AUTOSAR XML (schema 4-0-3)
standard types defined: uint8, Boolean, UInt16, UInt8
package /AUTOSAR_Platform/DataConstrs
  range DC_Boolean: raw 0..1
  range DC_UInt16: raw 0..65535
  range DC_UInt8: raw 0..255
package /DataTypes/Units
  unit NoUnit1: display-name=NoUnit, factor-si-to-unit=1, offset-si-to-unit=0
package /PATAC/Facility/DataTypes/Implementation
  compu method COMPU_Boolean: 0=FALSE, 1=TRUE
  unit NoUnit: factor-si-to-unit=1, offset-si-to-unit=0
package /PATAC/MSM/DataTypes
  parameter interface SeatMovCfg
    parameter data prototype Val: sw-calibration-access=READ-WRITE, type=UInt8
package /PATAC/MSM/DataTypes/ImplementationDataTypes
  impl type IfVeSMSeStNumConfig: category=VALUE, base-type=UInt8, sw-calibration-access=READ-ONLY, compu {0=SeatNum4Config, 1=SeatNum6Config, 2=SeatNum7Config, 3=SeatNum4PConfig, 4=SeatNumNDLBLow, 5=SeatNumNDLBHigh}, type-emitter=RTE
  impl type IntCnt: category=VALUE, base-type=UInt8, sw-calibration-access=READ-ONLY, type-emitter=RTE
  impl type IntEnable: category=VALUE, base-type=Boolean, sw-calibration-access=READ-ONLY, type-emitter=RTE
package /PATAC/MSM/ModeAdjust
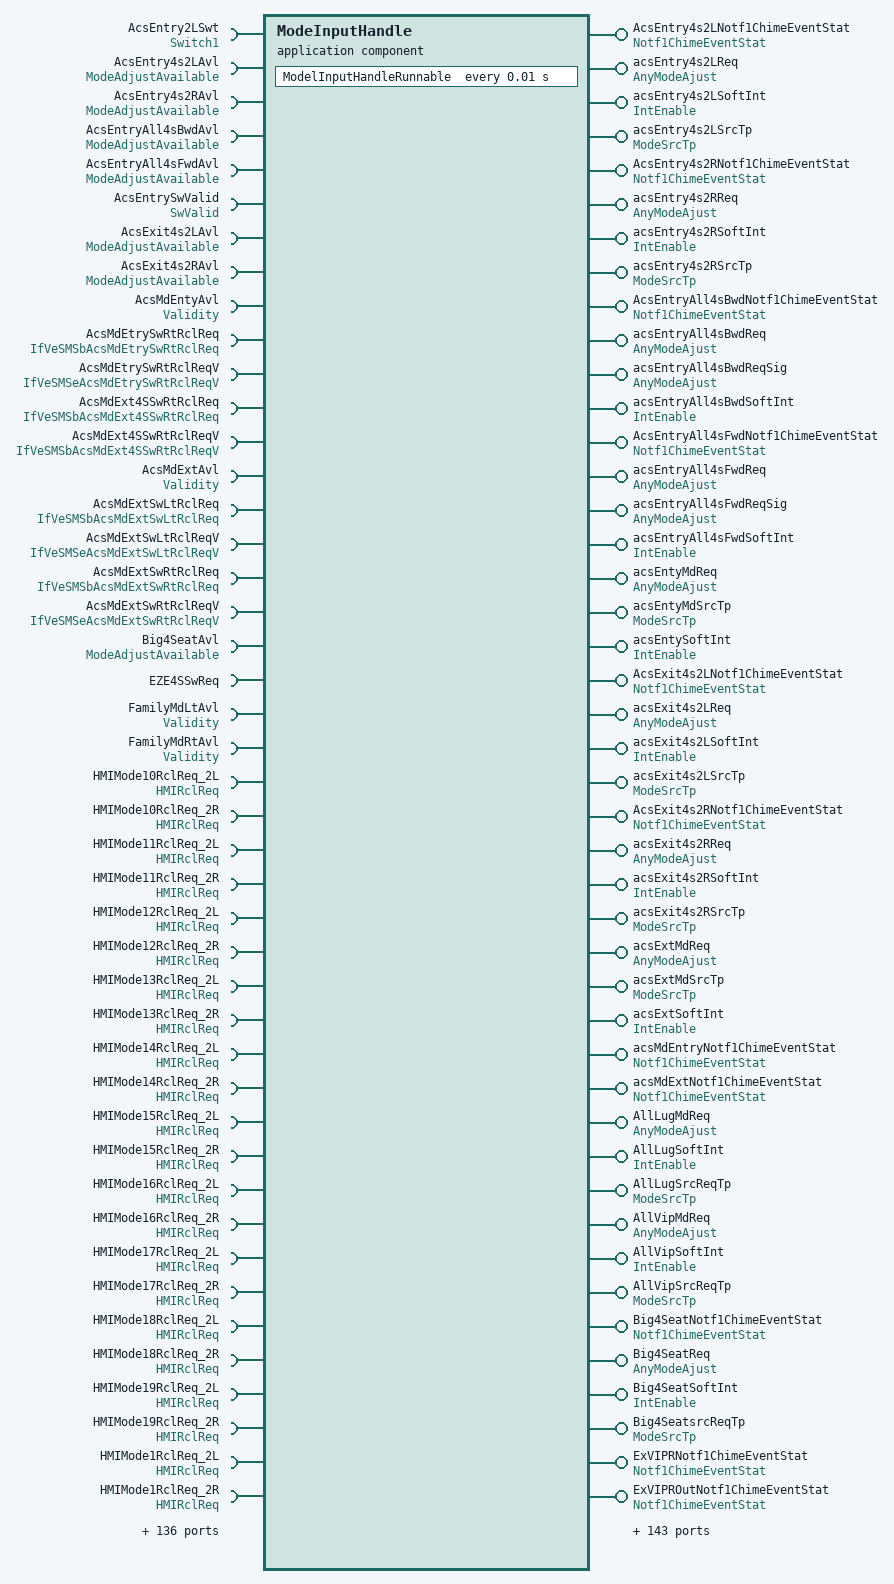
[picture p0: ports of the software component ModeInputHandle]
  application sw component type ModeInputHandle
    187 x provide port:
      AcsEntry4s2LNotf1ChimeEventStat: nonqueued-sender-com-spec{data-element=Notf1ChimeEventStat/Val, init-value=0}, provided-interface=Notf1ChimeEventStat
      acsEntry4s2LReq: nonqueued-sender-com-spec{data-element=AnyModeAjust/Val, init-value=0}, provided-interface=AnyModeAjust
      acsEntry4s2LSoftInt: nonqueued-sender-com-spec{data-element=IntEnable/Val, init-value=0}, provided-interface=IntEnable
      acsEntry4s2LSrcTp: nonqueued-sender-com-spec{data-element=ModeSrcTp/Val, init-value=0}, provided-interface=ModeSrcTp
      AcsEntry4s2RNotf1ChimeEventStat: nonqueued-sender-com-spec{data-element=Notf1ChimeEventStat/Val, init-value=0}, provided-interface=Notf1ChimeEventStat
      acsEntry4s2RReq: nonqueued-sender-com-spec{data-element=AnyModeAjust/Val, init-value=0}, provided-interface=AnyModeAjust
      acsEntry4s2RSoftInt: nonqueued-sender-com-spec{data-element=IntEnable/Val, init-value=0}, provided-interface=IntEnable
      acsEntry4s2RSrcTp: nonqueued-sender-com-spec{data-element=ModeSrcTp/Val, init-value=0}, provided-interface=ModeSrcTp
      AcsEntryAll4sBwdNotf1ChimeEventStat: nonqueued-sender-com-spec{data-element=Notf1ChimeEventStat/Val, init-value=0}, provided-interface=Notf1ChimeEventStat
      acsEntryAll4sBwdReq: nonqueued-sender-com-spec{data-element=AnyModeAjust/Val, init-value=0}, provided-interface=AnyModeAjust
      acsEntryAll4sBwdReqSig: nonqueued-sender-com-spec{data-element=AnyModeAjust/Val, init-value=0}, provided-interface=AnyModeAjust
      acsEntryAll4sBwdSoftInt: nonqueued-sender-com-spec{data-element=IntEnable/Val, init-value=0}, provided-interface=IntEnable
      AcsEntryAll4sFwdNotf1ChimeEventStat: nonqueued-sender-com-spec{data-element=Notf1ChimeEventStat/Val, init-value=0}, provided-interface=Notf1ChimeEventStat
      acsEntryAll4sFwdReq: nonqueued-sender-com-spec{data-element=AnyModeAjust/Val, init-value=0}, provided-interface=AnyModeAjust
      acsEntryAll4sFwdReqSig: nonqueued-sender-com-spec{data-element=AnyModeAjust/Val, init-value=0}, provided-interface=AnyModeAjust
      acsEntryAll4sFwdSoftInt: nonqueued-sender-com-spec{data-element=IntEnable/Val, init-value=0}, provided-interface=IntEnable
      acsEntyMdReq: nonqueued-sender-com-spec{data-element=AnyModeAjust/Val, init-value=0}, provided-interface=AnyModeAjust
      acsEntyMdSrcTp: nonqueued-sender-com-spec{data-element=ModeSrcTp/Val, init-value=0}, provided-interface=ModeSrcTp
      acsEntySoftInt: nonqueued-sender-com-spec{data-element=IntEnable/Val, init-value=0}, provided-interface=IntEnable
      AcsExit4s2LNotf1ChimeEventStat: nonqueued-sender-com-spec{data-element=Notf1ChimeEventStat/Val, init-value=0}, provided-interface=Notf1ChimeEventStat
      acsExit4s2LReq: nonqueued-sender-com-spec{data-element=AnyModeAjust/Val, init-value=0}, provided-interface=AnyModeAjust
      acsExit4s2LSoftInt: nonqueued-sender-com-spec{data-element=IntEnable/Val, init-value=0}, provided-interface=IntEnable
      acsExit4s2LSrcTp: nonqueued-sender-com-spec{data-element=ModeSrcTp/Val, init-value=0}, provided-interface=ModeSrcTp
      AcsExit4s2RNotf1ChimeEventStat: nonqueued-sender-com-spec{data-element=Notf1ChimeEventStat/Val, init-value=0}, provided-interface=Notf1ChimeEventStat
      acsExit4s2RReq: nonqueued-sender-com-spec{data-element=AnyModeAjust/Val, init-value=0}, provided-interface=AnyModeAjust
      acsExit4s2RSoftInt: nonqueued-sender-com-spec{data-element=IntEnable/Val, init-value=0}, provided-interface=IntEnable
      acsExit4s2RSrcTp: nonqueued-sender-com-spec{data-element=ModeSrcTp/Val, init-value=0}, provided-interface=ModeSrcTp
      acsExtMdReq: nonqueued-sender-com-spec{data-element=AnyModeAjust/Val, init-value=0}, provided-interface=AnyModeAjust
      acsExtMdSrcTp: nonqueued-sender-com-spec{data-element=ModeSrcTp/Val, init-value=0}, provided-interface=ModeSrcTp
      acsExtSoftInt: nonqueued-sender-com-spec{data-element=IntEnable/Val, init-value=0}, provided-interface=IntEnable
      acsMdEntryNotf1ChimeEventStat: nonqueued-sender-com-spec{data-element=Notf1ChimeEventStat/Val, init-value=0}, provided-interface=Notf1ChimeEventStat
      acsMdExtNotf1ChimeEventStat: nonqueued-sender-com-spec{data-element=Notf1ChimeEventStat/Val, init-value=0}, provided-interface=Notf1ChimeEventStat
      AllLugMdReq: nonqueued-sender-com-spec{data-element=AnyModeAjust/Val, init-value=0}, provided-interface=AnyModeAjust
      AllLugSoftInt: nonqueued-sender-com-spec{data-element=IntEnable/Val, init-value=0}, provided-interface=IntEnable
      AllLugSrcReqTp: nonqueued-sender-com-spec{data-element=ModeSrcTp/Val, init-value=0}, provided-interface=ModeSrcTp
      AllVipMdReq: nonqueued-sender-com-spec{data-element=AnyModeAjust/Val, init-value=0}, provided-interface=AnyModeAjust
      AllVipSoftInt: nonqueued-sender-com-spec{data-element=IntEnable/Val, init-value=0}, provided-interface=IntEnable
      AllVipSrcReqTp: nonqueued-sender-com-spec{data-element=ModeSrcTp/Val, init-value=0}, provided-interface=ModeSrcTp
      Big4SeatNotf1ChimeEventStat: nonqueued-sender-com-spec{data-element=Notf1ChimeEventStat/Val, init-value=0}, provided-interface=Notf1ChimeEventStat
      Big4SeatReq: nonqueued-sender-com-spec{data-element=AnyModeAjust/Val, init-value=0}, provided-interface=AnyModeAjust
      Big4SeatSoftInt: nonqueued-sender-com-spec{data-element=IntEnable/Val, init-value=0}, provided-interface=IntEnable
      Big4SeatsrcReqTp: nonqueued-sender-com-spec{data-element=ModeSrcTp/Val, init-value=0}, provided-interface=ModeSrcTp
      ExVIPRNotf1ChimeEventStat: nonqueued-sender-com-spec{data-element=Notf1ChimeEventStat/Val, init-value=0}, provided-interface=Notf1ChimeEventStat
      ExVIPROutNotf1ChimeEventStat: nonqueued-sender-com-spec{data-element=Notf1ChimeEventStat/Val, init-value=0}, provided-interface=Notf1ChimeEventStat
      ExVIPROutReq: nonqueued-sender-com-spec{data-element=AnyModeAjust/Val, init-value=0}, provided-interface=AnyModeAjust
      ExVIPROutSoftInt: nonqueued-sender-com-spec{data-element=IntEnable/Val, init-value=0}, provided-interface=IntEnable
      ExVIPROutsrcReqTp: nonqueued-sender-com-spec{data-element=ModeSrcTp/Val, init-value=0}, provided-interface=ModeSrcTp
      ExVIPRReq: nonqueued-sender-com-spec{data-element=AnyModeAjust/Val, init-value=0}, provided-interface=AnyModeAjust
      ExVIPRSoftInt: nonqueued-sender-com-spec{data-element=IntEnable/Val, init-value=0}, provided-interface=IntEnable
      ExVIPRsrcReqTp: nonqueued-sender-com-spec{data-element=ModeSrcTp/Val, init-value=0}, provided-interface=ModeSrcTp
      FamilyMdNotf1ChimeEventStat: nonqueued-sender-com-spec{data-element=Notf1ChimeEventStat/Val, init-value=0}, provided-interface=Notf1ChimeEventStat
      IntimacyLtMdReq: nonqueued-sender-com-spec{data-element=AnyModeAjust/Val, init-value=0}, provided-interface=AnyModeAjust
      IntimacyLtMdSrcTp: nonqueued-sender-com-spec{data-element=ModeSrcTp/Val, init-value=0}, provided-interface=ModeSrcTp
      IntimacyLtSoftInt: nonqueued-sender-com-spec{data-element=IntEnable/Val, init-value=0}, provided-interface=IntEnable
      IntimacyMdNotf1ChimeEventStat: nonqueued-sender-com-spec{data-element=Notf1ChimeEventStat/Val, init-value=0}, provided-interface=Notf1ChimeEventStat
      IntimacyRtMdReq: nonqueued-sender-com-spec{data-element=AnyModeAjust/Val, init-value=0}, provided-interface=AnyModeAjust
      IntimacyRtMdSrcTp: nonqueued-sender-com-spec{data-element=ModeSrcTp/Val, init-value=0}, provided-interface=ModeSrcTp
      IntimacyRtSoftInt: nonqueued-sender-com-spec{data-element=IntEnable/Val, init-value=0}, provided-interface=IntEnable
      LgrstCloseLtMdReq: nonqueued-sender-com-spec{data-element=AnyModeAjust/Val, init-value=0}, provided-interface=AnyModeAjust
      LgrstCloseLtSoftInt: nonqueued-sender-com-spec{data-element=IntEnable/Val, init-value=0}, provided-interface=IntEnable
      LgrstCloseLtSrcReqTp: nonqueued-sender-com-spec{data-element=ModeSrcTp/Val, init-value=0}, provided-interface=ModeSrcTp
      LgrstCloseRtMdReq: nonqueued-sender-com-spec{data-element=AnyModeAjust/Val, init-value=0}, provided-interface=AnyModeAjust
      LgrstCloseRtSoftInt: nonqueued-sender-com-spec{data-element=IntEnable/Val, init-value=0}, provided-interface=IntEnable
      LgrstCloseRtSrcReqTp: nonqueued-sender-com-spec{data-element=ModeSrcTp/Val, init-value=0}, provided-interface=ModeSrcTp
      LgrstLtMdNotf1ChimeEventStat: nonqueued-sender-com-spec{data-element=Notf1ChimeEventStat/Val, init-value=0}, provided-interface=Notf1ChimeEventStat
      LgrstOpenLtMdReq: nonqueued-sender-com-spec{data-element=AnyModeAjust/Val, init-value=0}, provided-interface=AnyModeAjust
      LgrstOpenLtSoftInt: nonqueued-sender-com-spec{data-element=IntEnable/Val, init-value=0}, provided-interface=IntEnable
      LgrstOpenLtSrcReqTp: nonqueued-sender-com-spec{data-element=ModeSrcTp/Val, init-value=0}, provided-interface=ModeSrcTp
      LgrstOpenRtMdReq: nonqueued-sender-com-spec{data-element=AnyModeAjust/Val, init-value=0}, provided-interface=AnyModeAjust
      LgrstOpenRtSoftInt: nonqueued-sender-com-spec{data-element=IntEnable/Val, init-value=0}, provided-interface=IntEnable
      LgrstOpenRtSrcReqTp: nonqueued-sender-com-spec{data-element=ModeSrcTp/Val, init-value=0}, provided-interface=ModeSrcTp
      LgrstRtMdNotf1ChimeEventStat: nonqueued-sender-com-spec{data-element=Notf1ChimeEventStat/Val, init-value=0}, provided-interface=Notf1ChimeEventStat
      LtFamilyMdReq: nonqueued-sender-com-spec{data-element=AnyModeAjust/Val, init-value=0}, provided-interface=AnyModeAjust
      LtFamilySoftInt: nonqueued-sender-com-spec{data-element=IntEnable/Val, init-value=0}, provided-interface=IntEnable
      LtFamilySrcReqTp: nonqueued-sender-com-spec{data-element=ModeSrcTp/Val, init-value=0}, provided-interface=ModeSrcTp
      LtLugMdReq: nonqueued-sender-com-spec{data-element=AnyModeAjust/Val, init-value=0}, provided-interface=AnyModeAjust
      LtLugSoftInt: nonqueued-sender-com-spec{data-element=IntEnable/Val, init-value=0}, provided-interface=IntEnable
      LtLugSrcReqTp: nonqueued-sender-com-spec{data-element=ModeSrcTp/Val, init-value=0}, provided-interface=ModeSrcTp
      LtLyingMdReq: nonqueued-sender-com-spec{data-element=AnyModeAjust/Val, init-value=0}, provided-interface=AnyModeAjust
      LtLyingSoftInt: nonqueued-sender-com-spec{data-element=IntEnable/Val, init-value=0}, provided-interface=IntEnable
      LtLyingSrcReqTp: nonqueued-sender-com-spec{data-element=ModeSrcTp/Val, init-value=0}, provided-interface=ModeSrcTp
      LtRcvyMdReq: nonqueued-sender-com-spec{data-element=AnyModeAjust/Val, init-value=0}, provided-interface=AnyModeAjust
      LtRcvySoftInt: nonqueued-sender-com-spec{data-element=IntEnable/Val, init-value=0}, provided-interface=IntEnable
      LtRcvySrcReqTp: nonqueued-sender-com-spec{data-element=ModeSrcTp/Val, init-value=0}, provided-interface=ModeSrcTp
      LtVipMdReq: nonqueued-sender-com-spec{data-element=AnyModeAjust/Val, init-value=0}, provided-interface=AnyModeAjust
      LtVipSoftInt: nonqueued-sender-com-spec{data-element=IntEnable/Val, init-value=0}, provided-interface=IntEnable
      LtVipSrcReqTp: nonqueued-sender-com-spec{data-element=ModeSrcTp/Val, init-value=0}, provided-interface=ModeSrcTp
      LugMdNotf1ChimeEventStat: nonqueued-sender-com-spec{data-element=Notf1ChimeEventStat/Val, init-value=0}, provided-interface=Notf1ChimeEventStat
      LyingMdNotf1ChimeEventStat: nonqueued-sender-com-spec{data-element=Notf1ChimeEventStat/Val, init-value=0}, provided-interface=Notf1ChimeEventStat
      MdSWIntSrc: nonqueued-sender-com-spec{data-element=MdSWIntSrc/Val, init-value=0}, provided-interface=MdSWIntSrc
      PasReclinerEntryNotf1ChimeEventStat: nonqueued-sender-com-spec{data-element=Notf1ChimeEventStat/Val, init-value=0}, provided-interface=Notf1ChimeEventStat
      PasReclinerEntryReq: nonqueued-sender-com-spec{data-element=AnyModeAjust/Val, init-value=0}, provided-interface=AnyModeAjust
      PasReclinerEntrySoftInt: nonqueued-sender-com-spec{data-element=IntEnable/Val, init-value=0}, provided-interface=IntEnable
      PasReclinerEntrySrcReqTp: nonqueued-sender-com-spec{data-element=ModeSrcTp/Val, init-value=0}, provided-interface=ModeSrcTp
      PasReclinerExitNotf1ChimeEventStat: nonqueued-sender-com-spec{data-element=Notf1ChimeEventStat/Val, init-value=0}, provided-interface=Notf1ChimeEventStat
      PasReclinerExitReq: nonqueued-sender-com-spec{data-element=AnyModeAjust/Val, init-value=0}, provided-interface=AnyModeAjust
      PasReclinerExitSoftInt: nonqueued-sender-com-spec{data-element=IntEnable/Val, init-value=0}, provided-interface=IntEnable
      PasReclinerExitSrcReqTp: nonqueued-sender-com-spec{data-element=ModeSrcTp/Val, init-value=0}, provided-interface=ModeSrcTp
      RcvyMdNotf1ChimeEventStat: nonqueued-sender-com-spec{data-element=Notf1ChimeEventStat/Val, init-value=0}, provided-interface=Notf1ChimeEventStat
      RtFamilyMdReq: nonqueued-sender-com-spec{data-element=AnyModeAjust/Val, init-value=0}, provided-interface=AnyModeAjust
      RtFamilySoftInt: nonqueued-sender-com-spec{data-element=IntEnable/Val, init-value=0}, provided-interface=IntEnable
      RtFamilySrcReqTp: nonqueued-sender-com-spec{data-element=ModeSrcTp/Val, init-value=0}, provided-interface=ModeSrcTp
      RtLugMdReq: nonqueued-sender-com-spec{data-element=AnyModeAjust/Val, init-value=0}, provided-interface=AnyModeAjust
      RtLugSoftInt: nonqueued-sender-com-spec{data-element=IntEnable/Val, init-value=0}, provided-interface=IntEnable
      RtLugSrcReqTp: nonqueued-sender-com-spec{data-element=ModeSrcTp/Val, init-value=0}, provided-interface=ModeSrcTp
      RtLyingMdReq: nonqueued-sender-com-spec{data-element=AnyModeAjust/Val, init-value=0}, provided-interface=AnyModeAjust
      RtLyingSoftInt: nonqueued-sender-com-spec{data-element=IntEnable/Val, init-value=0}, provided-interface=IntEnable
      RtLyingSrcReqTp: nonqueued-sender-com-spec{data-element=ModeSrcTp/Val, init-value=0}, provided-interface=ModeSrcTp
      RtRcvyMdReq: nonqueued-sender-com-spec{data-element=AnyModeAjust/Val, init-value=0}, provided-interface=AnyModeAjust
      RtRcvySoftInt: nonqueued-sender-com-spec{data-element=IntEnable/Val, init-value=0}, provided-interface=IntEnable
      RtRcvySrcReqTp: nonqueued-sender-com-spec{data-element=ModeSrcTp/Val, init-value=0}, provided-interface=ModeSrcTp
      RtVipMdReq: nonqueued-sender-com-spec{data-element=AnyModeAjust/Val, init-value=0}, provided-interface=AnyModeAjust
      RtVipSoftInt: nonqueued-sender-com-spec{data-element=IntEnable/Val, init-value=0}, provided-interface=IntEnable
      RtVipSrcReqTp: nonqueued-sender-com-spec{data-element=ModeSrcTp/Val, init-value=0}, provided-interface=ModeSrcTp
      SRSAcsEntry4s2LIntCnt: nonqueued-sender-com-spec{data-element=SwModeIntCnt/Val, init-value=0}, provided-interface=SwModeIntCnt
      SRSAcsEntry4s2RIntCnt: nonqueued-sender-com-spec{data-element=SwModeIntCnt/Val, init-value=0}, provided-interface=SwModeIntCnt
      SRSAcsEntyIntCnt: nonqueued-sender-com-spec{data-element=SwModeIntCnt/Val, init-value=0}, provided-interface=SwModeIntCnt
      SRSAcsExit4s2LIntCnt: nonqueued-sender-com-spec{data-element=SwModeIntCnt/Val, init-value=0}, provided-interface=SwModeIntCnt
      SRSAcsExit4s2RIntCnt: nonqueued-sender-com-spec{data-element=SwModeIntCnt/Val, init-value=0}, provided-interface=SwModeIntCnt
      SRSAcsExtIntCnt: nonqueued-sender-com-spec{data-element=SwModeIntCnt/Val, init-value=0}, provided-interface=SwModeIntCnt
      SRSAllLugIntCnt: nonqueued-sender-com-spec{data-element=SwModeIntCnt/Val, init-value=0}, provided-interface=SwModeIntCnt
      SRSAllVipIntCnt: nonqueued-sender-com-spec{data-element=SwModeIntCnt/Val, init-value=0}, provided-interface=SwModeIntCnt
      SRSIntimacyLtIntCnt: nonqueued-sender-com-spec{data-element=SwModeIntCnt/Val, init-value=0}, provided-interface=SwModeIntCnt
      SRSIntimacyRtIntCnt: nonqueued-sender-com-spec{data-element=SwModeIntCnt/Val, init-value=0}, provided-interface=SwModeIntCnt
      SRSLgrstCloseLtIntCnt: nonqueued-sender-com-spec{data-element=SwModeIntCnt/Val, init-value=0}, provided-interface=SwModeIntCnt
      SRSLgrstCloseRtIntCnt: nonqueued-sender-com-spec{data-element=SwModeIntCnt/Val, init-value=0}, provided-interface=SwModeIntCnt
      SRSLgrstOpenLtIntCnt: nonqueued-sender-com-spec{data-element=SwModeIntCnt/Val, init-value=0}, provided-interface=SwModeIntCnt
      SRSLgrstOpenRtIntCnt: nonqueued-sender-com-spec{data-element=SwModeIntCnt/Val, init-value=0}, provided-interface=SwModeIntCnt
      SRSLtFamilyIntCnt: nonqueued-sender-com-spec{data-element=SwModeIntCnt/Val, init-value=0}, provided-interface=SwModeIntCnt
      SRSLtLugIntCnt: nonqueued-sender-com-spec{data-element=SwModeIntCnt/Val, init-value=0}, provided-interface=SwModeIntCnt
      SRSLtLyingIntCnt: nonqueued-sender-com-spec{data-element=SwModeIntCnt/Val, init-value=0}, provided-interface=SwModeIntCnt
      SRSLtRcvyIntCnt: nonqueued-sender-com-spec{data-element=SwModeIntCnt/Val, init-value=0}, provided-interface=SwModeIntCnt
      SRSLtVipIntCnt: nonqueued-sender-com-spec{data-element=SwModeIntCnt/Val, init-value=0}, provided-interface=SwModeIntCnt
      SRSRtFamilyIntCnt: nonqueued-sender-com-spec{data-element=SwModeIntCnt/Val, init-value=0}, provided-interface=SwModeIntCnt
      SRSRtLugIntCnt: nonqueued-sender-com-spec{data-element=SwModeIntCnt/Val, init-value=0}, provided-interface=SwModeIntCnt
      SRSRtLyingIntCnt: nonqueued-sender-com-spec{data-element=SwModeIntCnt/Val, init-value=0}, provided-interface=SwModeIntCnt
      SRSRtRcvyIntCnt: nonqueued-sender-com-spec{data-element=SwModeIntCnt/Val, init-value=0}, provided-interface=SwModeIntCnt
      SRSRtVipIntCnt: nonqueued-sender-com-spec{data-element=SwModeIntCnt/Val, init-value=0}, provided-interface=SwModeIntCnt
      SwAcsEntry4s2LIntCnt: nonqueued-sender-com-spec{data-element=SwModeIntCnt/Val, init-value=0}, provided-interface=SwModeIntCnt
      SwAcsEntry4s2RIntCnt: nonqueued-sender-com-spec{data-element=SwModeIntCnt/Val, init-value=0}, provided-interface=SwModeIntCnt
      SwAcsEntyBIntCnt: nonqueued-sender-com-spec{data-element=SwModeIntCnt/Val, init-value=0}, provided-interface=SwModeIntCnt
      SwAcsEntyLIntCnt: nonqueued-sender-com-spec{data-element=SwModeIntCnt/Val, init-value=0}, provided-interface=SwModeIntCnt
      SwAcsEntyRIntCnt: nonqueued-sender-com-spec{data-element=SwModeIntCnt/Val, init-value=0}, provided-interface=SwModeIntCnt
      SwAcsExit4s2LIntCnt: nonqueued-sender-com-spec{data-element=SwModeIntCnt/Val, init-value=0}, provided-interface=SwModeIntCnt
      SwAcsExit4s2RIntCnt: nonqueued-sender-com-spec{data-element=SwModeIntCnt/Val, init-value=0}, provided-interface=SwModeIntCnt
      SwAcsExtLIntCnt: nonqueued-sender-com-spec{data-element=SwModeIntCnt/Val, init-value=0}, provided-interface=SwModeIntCnt
      SwAcsExtRIntCnt: nonqueued-sender-com-spec{data-element=SwModeIntCnt/Val, init-value=0}, provided-interface=SwModeIntCnt
      SwAllLugIntCnt: nonqueued-sender-com-spec{data-element=SwModeIntCnt/Val, init-value=0}, provided-interface=SwModeIntCnt
      SwLfVipIntCnt: nonqueued-sender-com-spec{data-element=SwModeIntCnt/Val, init-value=0}, provided-interface=SwModeIntCnt
      SwLtLugIntCnt: nonqueued-sender-com-spec{data-element=SwModeIntCnt/Val, init-value=0}, provided-interface=SwModeIntCnt
      SwLtRcvyIntCnt: nonqueued-sender-com-spec{data-element=SwModeIntCnt/Val, init-value=0}, provided-interface=SwModeIntCnt
      SwPasReclinerEntryIntCnt: nonqueued-sender-com-spec{data-element=SwModeIntCnt/Val, init-value=0}, provided-interface=SwModeIntCnt
      SwPasReclinerExitIntCnt: nonqueued-sender-com-spec{data-element=SwModeIntCnt/Val, init-value=0}, provided-interface=SwModeIntCnt
      SwRtLugIntCnt: nonqueued-sender-com-spec{data-element=SwModeIntCnt/Val, init-value=0}, provided-interface=SwModeIntCnt
      SwRtRcvyIntCnt: nonqueued-sender-com-spec{data-element=SwModeIntCnt/Val, init-value=0}, provided-interface=SwModeIntCnt
      SwRtVipIntCnt: nonqueued-sender-com-spec{data-element=SwModeIntCnt/Val, init-value=0}, provided-interface=SwModeIntCnt
      SwUnfold3LIntCnt: nonqueued-sender-com-spec{data-element=SwModeIntCnt/Val, init-value=0}, provided-interface=SwModeIntCnt
      SwUnfold3RIntCnt: nonqueued-sender-com-spec{data-element=SwModeIntCnt/Val, init-value=0}, provided-interface=SwModeIntCnt
      Unfold3LNotf1ChimeEventStat: nonqueued-sender-com-spec{data-element=Notf1ChimeEventStat/Val, init-value=0}, provided-interface=Notf1ChimeEventStat
      Unfold3LReq: nonqueued-sender-com-spec{data-element=AnyModeAjust/Val, init-value=0}, provided-interface=AnyModeAjust
      Unfold3LSoftInt: nonqueued-sender-com-spec{data-element=IntEnable/Val, init-value=0}, provided-interface=IntEnable
      Unfold3LsrcReqTp: nonqueued-sender-com-spec{data-element=ModeSrcTp/Val, init-value=0}, provided-interface=ModeSrcTp
      Unfold3RNotf1ChimeEventStat: nonqueued-sender-com-spec{data-element=Notf1ChimeEventStat/Val, init-value=0}, provided-interface=Notf1ChimeEventStat
      Unfold3RReq: nonqueued-sender-com-spec{data-element=AnyModeAjust/Val, init-value=0}, provided-interface=AnyModeAjust
      Unfold3RSoftInt: nonqueued-sender-com-spec{data-element=IntEnable/Val, init-value=0}, provided-interface=IntEnable
      Unfold3RsrcReqTp: nonqueued-sender-com-spec{data-element=ModeSrcTp/Val, init-value=0}, provided-interface=ModeSrcTp
      VIPAllOutNotf1ChimeEventStat: nonqueued-sender-com-spec{data-element=Notf1ChimeEventStat/Val, init-value=0}, provided-interface=Notf1ChimeEventStat
      VIPAllOutReq: nonqueued-sender-com-spec{data-element=AnyModeAjust/Val, init-value=0}, provided-interface=AnyModeAjust
      VIPAllOutSoftInt: nonqueued-sender-com-spec{data-element=IntEnable/Val, init-value=0}, provided-interface=IntEnable
      VIPAllOutsrcReqTp: nonqueued-sender-com-spec{data-element=ModeSrcTp/Val, init-value=0}, provided-interface=ModeSrcTp
      VIPLtOutNotf1ChimeEventStat: nonqueued-sender-com-spec{data-element=Notf1ChimeEventStat/Val, init-value=0}, provided-interface=Notf1ChimeEventStat
      VIPLtOutReq: nonqueued-sender-com-spec{data-element=AnyModeAjust/Val, init-value=0}, provided-interface=AnyModeAjust
      VIPLtOutSoftInt: nonqueued-sender-com-spec{data-element=IntEnable/Val, init-value=0}, provided-interface=IntEnable
      VIPLtOutsrcReqTp: nonqueued-sender-com-spec{data-element=ModeSrcTp/Val, init-value=0}, provided-interface=ModeSrcTp
      VipMdNotf1ChimeEventStat: nonqueued-sender-com-spec{data-element=Notf1ChimeEventStat/Val, init-value=0}, provided-interface=Notf1ChimeEventStat
      VIPRtOutNotf1ChimeEventStat: nonqueued-sender-com-spec{data-element=Notf1ChimeEventStat/Val, init-value=0}, provided-interface=Notf1ChimeEventStat
      VIPRtOutReq: nonqueued-sender-com-spec{data-element=AnyModeAjust/Val, init-value=0}, provided-interface=AnyModeAjust
      VIPRtOutSoftInt: nonqueued-sender-com-spec{data-element=IntEnable/Val, init-value=0}, provided-interface=IntEnable
      VIPRtOutsrcReqTp: nonqueued-sender-com-spec{data-element=ModeSrcTp/Val, init-value=0}, provided-interface=ModeSrcTp
      WholeVehMem1Notf1ChimeEventStat: nonqueued-sender-com-spec{data-element=Notf1ChimeEventStat/Val, init-value=0}, provided-interface=Notf1ChimeEventStat
      WholeVehMem1Req: nonqueued-sender-com-spec{data-element=AnyModeAjust/Val, init-value=0}, provided-interface=AnyModeAjust
      WholeVehMem1SoftInt: nonqueued-sender-com-spec{data-element=IntEnable/Val, init-value=0}, provided-interface=IntEnable
      WholeVehMem1srcReqTp: nonqueued-sender-com-spec{data-element=ModeSrcTp/Val, init-value=0}, provided-interface=ModeSrcTp
      WholeVehMem2Notf1ChimeEventStat: nonqueued-sender-com-spec{data-element=Notf1ChimeEventStat/Val, init-value=0}, provided-interface=Notf1ChimeEventStat
      WholeVehMem2Req: nonqueued-sender-com-spec{data-element=AnyModeAjust/Val, init-value=0}, provided-interface=AnyModeAjust
      WholeVehMem2SoftInt: nonqueued-sender-com-spec{data-element=IntEnable/Val, init-value=0}, provided-interface=IntEnable
      WholeVehMem2srcReqTp: nonqueued-sender-com-spec{data-element=ModeSrcTp/Val, init-value=0}, provided-interface=ModeSrcTp
    221 x require port:
      AcsEntry2LSwt: nonqueued-receiver-com-spec{data-element=Switch1/Val, filter=data-filter-type=ALWAYS, init-value=0}, required-interface=Switch1
      AcsEntry4s2LAvl: nonqueued-receiver-com-spec{data-element=ModeAdjustAvailable/Val, filter=data-filter-type=ALWAYS, init-value=0}, required-interface=ModeAdjustAvailable
      AcsEntry4s2RAvl: nonqueued-receiver-com-spec{data-element=ModeAdjustAvailable/Val, filter=data-filter-type=ALWAYS, init-value=0}, required-interface=ModeAdjustAvailable
      AcsEntryAll4sBwdAvl: nonqueued-receiver-com-spec{data-element=ModeAdjustAvailable/Val, filter=data-filter-type=ALWAYS, init-value=0}, required-interface=ModeAdjustAvailable
      AcsEntryAll4sFwdAvl: nonqueued-receiver-com-spec{data-element=ModeAdjustAvailable/Val, filter=data-filter-type=ALWAYS, init-value=0}, required-interface=ModeAdjustAvailable
      AcsEntrySwValid: nonqueued-receiver-com-spec{data-element=SwValid/Val, filter=data-filter-type=ALWAYS, init-value=0}, required-interface=SwValid
      AcsExit4s2LAvl: nonqueued-receiver-com-spec{data-element=ModeAdjustAvailable/Val, filter=data-filter-type=ALWAYS, init-value=0}, required-interface=ModeAdjustAvailable
      AcsExit4s2RAvl: nonqueued-receiver-com-spec{data-element=ModeAdjustAvailable/Val, filter=data-filter-type=ALWAYS, init-value=0}, required-interface=ModeAdjustAvailable
      AcsMdEntyAvl: nonqueued-receiver-com-spec{data-element=Validity/Val, filter=data-filter-type=ALWAYS, init-value=0}, required-interface=Validity
      AcsMdEtrySwRtRclReq: nonqueued-receiver-com-spec{data-element=IfVeSMSbAcsMdEtrySwRtRclReq/Val, filter=data-filter-type=ALWAYS, init-value=0}, required-interface=IfVeSMSbAcsMdEtrySwRtRclReq
      AcsMdEtrySwRtRclReqV: nonqueued-receiver-com-spec{data-element=IfVeSMSeAcsMdEtrySwRtRclReqV/Val, filter=data-filter-type=ALWAYS, init-value=0}, required-interface=IfVeSMSeAcsMdEtrySwRtRclReqV
      AcsMdExt4SSwRtRclReq: nonqueued-receiver-com-spec{data-element=IfVeSMSbAcsMdExt4SSwRtRclReq/Val, filter=data-filter-type=ALWAYS, init-value=0}, required-interface=IfVeSMSbAcsMdExt4SSwRtRclReq
      AcsMdExt4SSwRtRclReqV: nonqueued-receiver-com-spec{data-element=IfVeSMSbAcsMdExt4SSwRtRclReqV/Val, filter=data-filter-type=ALWAYS, init-value=0}, required-interface=IfVeSMSbAcsMdExt4SSwRtRclReqV
      AcsMdExtAvl: nonqueued-receiver-com-spec{data-element=Validity/Val, filter=data-filter-type=ALWAYS, init-value=0}, required-interface=Validity
      AcsMdExtSwLtRclReq: nonqueued-receiver-com-spec{data-element=IfVeSMSbAcsMdExtSwLtRclReq/Val, filter=data-filter-type=ALWAYS, init-value=0}, required-interface=IfVeSMSbAcsMdExtSwLtRclReq
      AcsMdExtSwLtRclReqV: nonqueued-receiver-com-spec{data-element=IfVeSMSeAcsMdExtSwLtRclReqV/Val, filter=data-filter-type=ALWAYS, init-value=0}, required-interface=IfVeSMSeAcsMdExtSwLtRclReqV
      AcsMdExtSwRtRclReq: nonqueued-receiver-com-spec{data-element=IfVeSMSbAcsMdExtSwRtRclReq/Val, filter=data-filter-type=ALWAYS, init-value=0}, required-interface=IfVeSMSbAcsMdExtSwRtRclReq
      AcsMdExtSwRtRclReqV: nonqueued-receiver-com-spec{data-element=IfVeSMSeAcsMdExtSwRtRclReqV/Val, filter=data-filter-type=ALWAYS, init-value=0}, required-interface=IfVeSMSeAcsMdExtSwRtRclReqV
      Big4SeatAvl: nonqueued-receiver-com-spec{data-element=ModeAdjustAvailable/Val, filter=data-filter-type=ALWAYS, init-value=0}, required-interface=ModeAdjustAvailable
      EZE4SSwReq: nonqueued-receiver-com-spec{data-element=EZE4SSwReq/Val, filter=data-filter-type=ALWAYS, init-value=0}, required-interface=EZE4SSwReq
      FamilyMdLtAvl: nonqueued-receiver-com-spec{data-element=Validity/Val, filter=data-filter-type=ALWAYS, init-value=0}, required-interface=Validity
      FamilyMdRtAvl: nonqueued-receiver-com-spec{data-element=Validity/Val, filter=data-filter-type=ALWAYS, init-value=0}, required-interface=Validity
      HMIMode10RclReq_2L: nonqueued-receiver-com-spec{data-element=HMIRclReq/Val, filter=data-filter-type=ALWAYS, init-value=0}, required-interface=HMIRclReq
      HMIMode10RclReq_2R: nonqueued-receiver-com-spec{data-element=HMIRclReq/Val, filter=data-filter-type=ALWAYS, init-value=0}, required-interface=HMIRclReq
      HMIMode11RclReq_2L: nonqueued-receiver-com-spec{data-element=HMIRclReq/Val, filter=data-filter-type=ALWAYS, init-value=0}, required-interface=HMIRclReq
      HMIMode11RclReq_2R: nonqueued-receiver-com-spec{data-element=HMIRclReq/Val, filter=data-filter-type=ALWAYS, init-value=0}, required-interface=HMIRclReq
      HMIMode12RclReq_2L: nonqueued-receiver-com-spec{data-element=HMIRclReq/Val, filter=data-filter-type=ALWAYS, init-value=0}, required-interface=HMIRclReq
      HMIMode12RclReq_2R: nonqueued-receiver-com-spec{data-element=HMIRclReq/Val, filter=data-filter-type=ALWAYS, init-value=0}, required-interface=HMIRclReq
      HMIMode13RclReq_2L: nonqueued-receiver-com-spec{data-element=HMIRclReq/Val, filter=data-filter-type=ALWAYS, init-value=0}, required-interface=HMIRclReq
      HMIMode13RclReq_2R: nonqueued-receiver-com-spec{data-element=HMIRclReq/Val, filter=data-filter-type=ALWAYS, init-value=0}, required-interface=HMIRclReq
      HMIMode14RclReq_2L: nonqueued-receiver-com-spec{data-element=HMIRclReq/Val, filter=data-filter-type=ALWAYS, init-value=0}, required-interface=HMIRclReq
      HMIMode14RclReq_2R: nonqueued-receiver-com-spec{data-element=HMIRclReq/Val, filter=data-filter-type=ALWAYS, init-value=0}, required-interface=HMIRclReq
      HMIMode15RclReq_2L: nonqueued-receiver-com-spec{data-element=HMIRclReq/Val, filter=data-filter-type=ALWAYS, init-value=0}, required-interface=HMIRclReq
      HMIMode15RclReq_2R: nonqueued-receiver-com-spec{data-element=HMIRclReq/Val, filter=data-filter-type=ALWAYS, init-value=0}, required-interface=HMIRclReq
      HMIMode16RclReq_2L: nonqueued-receiver-com-spec{data-element=HMIRclReq/Val, filter=data-filter-type=ALWAYS, init-value=0}, required-interface=HMIRclReq
      HMIMode16RclReq_2R: nonqueued-receiver-com-spec{data-element=HMIRclReq/Val, filter=data-filter-type=ALWAYS, init-value=0}, required-interface=HMIRclReq
      HMIMode17RclReq_2L: nonqueued-receiver-com-spec{data-element=HMIRclReq/Val, filter=data-filter-type=ALWAYS, init-value=0}, required-interface=HMIRclReq
      HMIMode17RclReq_2R: nonqueued-receiver-com-spec{data-element=HMIRclReq/Val, filter=data-filter-type=ALWAYS, init-value=0}, required-interface=HMIRclReq
      HMIMode18RclReq_2L: nonqueued-receiver-com-spec{data-element=HMIRclReq/Val, filter=data-filter-type=ALWAYS, init-value=0}, required-interface=HMIRclReq
      HMIMode18RclReq_2R: nonqueued-receiver-com-spec{data-element=HMIRclReq/Val, filter=data-filter-type=ALWAYS, init-value=0}, required-interface=HMIRclReq
      HMIMode19RclReq_2L: nonqueued-receiver-com-spec{data-element=HMIRclReq/Val, filter=data-filter-type=ALWAYS, init-value=0}, required-interface=HMIRclReq
      HMIMode19RclReq_2R: nonqueued-receiver-com-spec{data-element=HMIRclReq/Val, filter=data-filter-type=ALWAYS, init-value=0}, required-interface=HMIRclReq
      HMIMode1RclReq_2L: nonqueued-receiver-com-spec{data-element=HMIRclReq/Val, filter=data-filter-type=ALWAYS, init-value=0}, required-interface=HMIRclReq
      HMIMode1RclReq_2R: nonqueued-receiver-com-spec{data-element=HMIRclReq/Val, filter=data-filter-type=ALWAYS, init-value=0}, required-interface=HMIRclReq
      HMIMode20RclReq_2L: nonqueued-receiver-com-spec{data-element=HMIRclReq/Val, filter=data-filter-type=ALWAYS, init-value=0}, required-interface=HMIRclReq
      HMIMode20RclReq_2R: nonqueued-receiver-com-spec{data-element=HMIRclReq/Val, filter=data-filter-type=ALWAYS, init-value=0}, required-interface=HMIRclReq
      HMIMode21RclReq_2L: nonqueued-receiver-com-spec{data-element=HMIRclReq/Val, filter=data-filter-type=ALWAYS, init-value=0}, required-interface=HMIRclReq
      HMIMode21RclReq_2R: nonqueued-receiver-com-spec{data-element=HMIRclReq/Val, filter=data-filter-type=ALWAYS, init-value=0}, required-interface=HMIRclReq
      HMIMode22RclReq_2L: nonqueued-receiver-com-spec{data-element=HMIRclReq/Val, filter=data-filter-type=ALWAYS, init-value=0}, required-interface=HMIRclReq
      HMIMode22RclReq_2R: nonqueued-receiver-com-spec{data-element=HMIRclReq/Val, filter=data-filter-type=ALWAYS, init-value=0}, required-interface=HMIRclReq
      HMIMode23RclReq_2L: nonqueued-receiver-com-spec{data-element=HMIRclReq/Val, filter=data-filter-type=ALWAYS, init-value=0}, required-interface=HMIRclReq
      HMIMode23RclReq_2R: nonqueued-receiver-com-spec{data-element=HMIRclReq/Val, filter=data-filter-type=ALWAYS, init-value=0}, required-interface=HMIRclReq
      HMIMode24RclReq_2L: nonqueued-receiver-com-spec{data-element=HMIRclReq/Val, filter=data-filter-type=ALWAYS, init-value=0}, required-interface=HMIRclReq
      HMIMode24RclReq_2R: nonqueued-receiver-com-spec{data-element=HMIRclReq/Val, filter=data-filter-type=ALWAYS, init-value=0}, required-interface=HMIRclReq
      HMIMode25RclReq_2L: nonqueued-receiver-com-spec{data-element=HMIRclReq/Val, filter=data-filter-type=ALWAYS, init-value=0}, required-interface=HMIRclReq
      HMIMode25RclReq_2R: nonqueued-receiver-com-spec{data-element=HMIRclReq/Val, filter=data-filter-type=ALWAYS, init-value=0}, required-interface=HMIRclReq
      HMIMode26RclReq_2L: nonqueued-receiver-com-spec{data-element=HMIRclReq/Val, filter=data-filter-type=ALWAYS, init-value=0}, required-interface=HMIRclReq
      HMIMode26RclReq_2R: nonqueued-receiver-com-spec{data-element=HMIRclReq/Val, filter=data-filter-type=ALWAYS, init-value=0}, required-interface=HMIRclReq
      HMIMode27RclReq_2L: nonqueued-receiver-com-spec{data-element=HMIRclReq/Val, filter=data-filter-type=ALWAYS, init-value=0}, required-interface=HMIRclReq
      HMIMode27RclReq_2R: nonqueued-receiver-com-spec{data-element=HMIRclReq/Val, filter=data-filter-type=ALWAYS, init-value=0}, required-interface=HMIRclReq
      HMIMode28RclReq_2L: nonqueued-receiver-com-spec{data-element=HMIRclReq/Val, filter=data-filter-type=ALWAYS, init-value=0}, required-interface=HMIRclReq
      HMIMode28RclReq_2R: nonqueued-receiver-com-spec{data-element=HMIRclReq/Val, filter=data-filter-type=ALWAYS, init-value=0}, required-interface=HMIRclReq
      HMIMode29RclReq_2L: nonqueued-receiver-com-spec{data-element=HMIRclReq/Val, filter=data-filter-type=ALWAYS, init-value=0}, required-interface=HMIRclReq
      HMIMode29RclReq_2R: nonqueued-receiver-com-spec{data-element=HMIRclReq/Val, filter=data-filter-type=ALWAYS, init-value=0}, required-interface=HMIRclReq
      HMIMode2RclReq_2L: nonqueued-receiver-com-spec{data-element=HMIRclReq/Val, filter=data-filter-type=ALWAYS, init-value=0}, required-interface=HMIRclReq
      HMIMode2RclReq_2R: nonqueued-receiver-com-spec{data-element=HMIRclReq/Val, filter=data-filter-type=ALWAYS, init-value=0}, required-interface=HMIRclReq
      HMIMode30RclReq_2L: nonqueued-receiver-com-spec{data-element=HMIRclReq/Val, filter=data-filter-type=ALWAYS, init-value=0}, required-interface=HMIRclReq
      HMIMode30RclReq_2R: nonqueued-receiver-com-spec{data-element=HMIRclReq/Val, filter=data-filter-type=ALWAYS, init-value=0}, required-interface=HMIRclReq
      HMIMode31RclReq_2L: nonqueued-receiver-com-spec{data-element=HMIRclReq/Val, filter=data-filter-type=ALWAYS, init-value=0}, required-interface=HMIRclReq
      HMIMode31RclReq_2R: nonqueued-receiver-com-spec{data-element=HMIRclReq/Val, filter=data-filter-type=ALWAYS, init-value=0}, required-interface=HMIRclReq
      HMIMode32RclReq_2L: nonqueued-receiver-com-spec{data-element=HMIRclReq/Val, filter=data-filter-type=ALWAYS, init-value=0}, required-interface=HMIRclReq
      HMIMode32RclReq_2R: nonqueued-receiver-com-spec{data-element=HMIRclReq/Val, filter=data-filter-type=ALWAYS, init-value=0}, required-interface=HMIRclReq
      HMIMode3RclReq_2L: nonqueued-receiver-com-spec{data-element=HMIRclReq/Val, filter=data-filter-type=ALWAYS, init-value=0}, required-interface=HMIRclReq
      HMIMode3RclReq_2R: nonqueued-receiver-com-spec{data-element=HMIRclReq/Val, filter=data-filter-type=ALWAYS, init-value=0}, required-interface=HMIRclReq
      HMIMode4RclReq_2L: nonqueued-receiver-com-spec{data-element=HMIRclReq/Val, filter=data-filter-type=ALWAYS, init-value=0}, required-interface=HMIRclReq
      HMIMode4RclReq_2R: nonqueued-receiver-com-spec{data-element=HMIRclReq/Val, filter=data-filter-type=ALWAYS, init-value=0}, required-interface=HMIRclReq
      HMIMode5RclReq_2L: nonqueued-receiver-com-spec{data-element=HMIRclReq/Val, filter=data-filter-type=ALWAYS, init-value=0}, required-interface=HMIRclReq
      HMIMode5RclReq_2R: nonqueued-receiver-com-spec{data-element=HMIRclReq/Val, filter=data-filter-type=ALWAYS, init-value=0}, required-interface=HMIRclReq
      HMIMode6RclReq_2L: nonqueued-receiver-com-spec{data-element=HMIRclReq/Val, filter=data-filter-type=ALWAYS, init-value=0}, required-interface=HMIRclReq
      HMIMode6RclReq_2R: nonqueued-receiver-com-spec{data-element=HMIRclReq/Val, filter=data-filter-type=ALWAYS, init-value=0}, required-interface=HMIRclReq
      HMIMode7RclReq_2L: nonqueued-receiver-com-spec{data-element=HMIRclReq/Val, filter=data-filter-type=ALWAYS, init-value=0}, required-interface=HMIRclReq
      HMIMode7RclReq_2R: nonqueued-receiver-com-spec{data-element=HMIRclReq/Val, filter=data-filter-type=ALWAYS, init-value=0}, required-interface=HMIRclReq
      HMIMode8RclReq_2L: nonqueued-receiver-com-spec{data-element=HMIRclReq/Val, filter=data-filter-type=ALWAYS, init-value=0}, required-interface=HMIRclReq
      HMIMode8RclReq_2R: nonqueued-receiver-com-spec{data-element=HMIRclReq/Val, filter=data-filter-type=ALWAYS, init-value=0}, required-interface=HMIRclReq
      HMIMode9RclReq_2L: nonqueued-receiver-com-spec{data-element=HMIRclReq/Val, filter=data-filter-type=ALWAYS, init-value=0}, required-interface=HMIRclReq
      HMIMode9RclReq_2R: nonqueued-receiver-com-spec{data-element=HMIRclReq/Val, filter=data-filter-type=ALWAYS, init-value=0}, required-interface=HMIRclReq
      IfVeSMSbRrRcvyMdSwRclReq: nonqueued-receiver-com-spec{data-element=SeatSwReq/Val, filter=data-filter-type=ALWAYS, init-value=0}, required-interface=SeatSwReq
      IfVeSMSbRrRcvyMdSwRclReqV: nonqueued-receiver-com-spec{data-element=SeatSwReqV/Val, filter=data-filter-type=ALWAYS, init-value=0}, required-interface=SeatSwReqV
      IfVeSMSeStNumConfig: nonqueued-receiver-com-spec{data-element=IfVeSMSeStNumConfig/Val, filter=data-filter-type=ALWAYS, init-value=2}, required-interface=IfVeSMSeStNumConfig
      IfVeSMSeVipMdSwRtRclReqV: nonqueued-receiver-com-spec{data-element=IfVeSMSeVipMdSwRtRclReqV/Val, filter=data-filter-type=ALWAYS, init-value=0}, required-interface=IfVeSMSeVipMdSwRtRclReqV
      IntimacyLMdAvl: nonqueued-receiver-com-spec{data-element=Validity/Val, filter=data-filter-type=ALWAYS, init-value=0}, required-interface=Validity
      IntimacyRMdAvl: nonqueued-receiver-com-spec{data-element=ModeAdjustAvailable/Val, filter=data-filter-type=ALWAYS, init-value=0}, required-interface=ModeAdjustAvailable
      KeSMSuButtonLongPressedThrshldTm: parameter-require-com-spec{init-value=100, parameter=KeSMSuButtonLongPressedThrshldTm/Val}, required-interface=KeSMSuButtonLongPressedThrshldTm
      KeSMSuFoldType: parameter-require-com-spec{init-value=1, parameter=SeatMovCfg/Val}, required-interface=SeatMovCfg
      KeSMSwSeatSMSSeatMdTrigGapTimer: parameter-require-com-spec{init-value=25500, parameter=IfKeSMSwSeatSMSSeatMdTrigGapTimer/Val}, required-interface=IfKeSMSwSeatSMSSeatMdTrigGapTimer
      KeSMSwSeatTrigWaitTimer: parameter-require-com-spec{init-value=1000, parameter=IfKeSMSwSeatTrigWaitTimer/Val}, required-interface=IfKeSMSwSeatTrigWaitTimer
      KeSMSwSRSActiveValidTm: parameter-require-com-spec{init-value=500, parameter=KeSMSwSRSActiveValidTm/Val}, required-interface=KeSMSwSRSActiveValidTm
      LckUlckActvtFunc: nonqueued-receiver-com-spec{data-element=LckUlckActvtFunc/Val, filter=data-filter-type=ALWAYS, init-value=0}, required-interface=LckUlckActvtFunc
      LgrstCloseLtMdAvl: nonqueued-receiver-com-spec{data-element=ModeAdjustAvailable/Val, filter=data-filter-type=ALWAYS, init-value=0}, required-interface=ModeAdjustAvailable
      LgrstCloseRtMdAvl: nonqueued-receiver-com-spec{data-element=ModeAdjustAvailable/Val, filter=data-filter-type=ALWAYS, init-value=0}, required-interface=ModeAdjustAvailable
      LgrstOpenLtMdAvl: nonqueued-receiver-com-spec{data-element=ModeAdjustAvailable/Val, filter=data-filter-type=ALWAYS, init-value=0}, required-interface=ModeAdjustAvailable
      LgrstOpenRtMdAvl: nonqueued-receiver-com-spec{data-element=ModeAdjustAvailable/Val, filter=data-filter-type=ALWAYS, init-value=0}, required-interface=ModeAdjustAvailable
      LstLckChange: nonqueued-receiver-com-spec{data-element=LstLckChange/Val, filter=data-filter-type=ALWAYS, init-value=0}, required-interface=LstLckChange
      LstLckFunc: nonqueued-receiver-com-spec{data-element=LstLckFunc/Val, filter=data-filter-type=ALWAYS, init-value=0}, required-interface=LstLckFunc
      LugMdLtAvl: nonqueued-receiver-com-spec{data-element=Validity/Val, filter=data-filter-type=ALWAYS, init-value=0}, required-interface=Validity
      LugMdRtAvl: nonqueued-receiver-com-spec{data-element=Validity/Val, filter=data-filter-type=ALWAYS, init-value=0}, required-interface=Validity
      LugMdSwRclReq: nonqueued-receiver-com-spec{data-element=IfVeSMSbLugMdSwRclReq/Val, filter=data-filter-type=ALWAYS, init-value=0}, required-interface=IfVeSMSbLugMdSwRclReq
      LugMdSwRclReqV: nonqueued-receiver-com-spec{data-element=IfVeSMSeLugMdSwRclReqV/Val, filter=data-filter-type=ALWAYS, init-value=0}, required-interface=IfVeSMSeLugMdSwRclReqV
      LyingMdLtAvl: nonqueued-receiver-com-spec{data-element=Validity/Val, filter=data-filter-type=ALWAYS, init-value=0}, required-interface=Validity
      LyingMdRtAvl: nonqueued-receiver-com-spec{data-element=Validity/Val, filter=data-filter-type=ALWAYS, init-value=0}, required-interface=Validity
      M61WholeVehMemAvl: nonqueued-receiver-com-spec{data-element=ModeAdjustAvailable/Val, filter=data-filter-type=ALWAYS, init-value=0}, required-interface=ModeAdjustAvailable
      M62WholeVehMemAvl: nonqueued-receiver-com-spec{data-element=ModeAdjustAvailable/Val, filter=data-filter-type=ALWAYS, init-value=0}, required-interface=ModeAdjustAvailable
      ModeSrcTp: nonqueued-receiver-com-spec{data-element=ModeSrcTp/Val, filter=data-filter-type=ALWAYS, init-value=0}, required-interface=ModeSrcTp
      NotSecRowLeSeaOccStat: nonqueued-receiver-com-spec{data-element=SeatOccupiedState/Val, filter=data-filter-type=ALWAYS, init-value=0}, required-interface=SeatOccupiedState
      NotSecRowRtSeaOccStat: nonqueued-receiver-com-spec{data-element=SeatOccupiedState/Val, filter=data-filter-type=ALWAYS, init-value=0}, required-interface=SeatOccupiedState
      oModeState: nonqueued-receiver-com-spec{data-element=ModeState/Val, filter=data-filter-type=ALWAYS, init-value=0}, required-interface=ModeState
      PasReclinerAvl: nonqueued-receiver-com-spec{data-element=ModeAdjustAvailable/Val, filter=data-filter-type=ALWAYS, init-value=0}, required-interface=ModeAdjustAvailable
      PasReclinerExitAvl: nonqueued-receiver-com-spec{data-element=ModeAdjustAvailable/Val, filter=data-filter-type=ALWAYS, init-value=0}, required-interface=ModeAdjustAvailable
      PassStFldDnMovSwAct: nonqueued-receiver-com-spec{data-element=MovSwAct/Val, filter=data-filter-type=ALWAYS, init-value=0}, required-interface=MovSwAct
      PassStFldDnMovSwActV: nonqueued-receiver-com-spec{data-element=MovSwActV/Val, filter=data-filter-type=ALWAYS, init-value=0}, required-interface=MovSwActV
      PassStFldUpMovSwAct: nonqueued-receiver-com-spec{data-element=MovSwAct/Val, filter=data-filter-type=ALWAYS, init-value=0}, required-interface=MovSwAct
      PassStFldUpMovSwActV: nonqueued-receiver-com-spec{data-element=MovSwActV/Val, filter=data-filter-type=ALWAYS, init-value=0}, required-interface=MovSwActV
      RcvyMdLtAvl: nonqueued-receiver-com-spec{data-element=Validity/Val, filter=data-filter-type=ALWAYS, init-value=0}, required-interface=Validity
      RcvyMdRtAvl: nonqueued-receiver-com-spec{data-element=Validity/Val, filter=data-filter-type=ALWAYS, init-value=0}, required-interface=Validity
      RcvySwRtReq: nonqueued-receiver-com-spec{data-element=Switch/Val, filter=data-filter-type=ALWAYS, init-value=0}, required-interface=Switch
      RcvySwRtReqV: nonqueued-receiver-com-spec{data-element=Validity/Val, filter=data-filter-type=ALWAYS, init-value=0}, required-interface=Validity
      Recovery2LSwt: nonqueued-receiver-com-spec{data-element=Switch1/Val, filter=data-filter-type=ALWAYS, init-value=0}, required-interface=Switch1
      RLDoorAjarSwAct: nonqueued-receiver-com-spec{data-element=DoorAjarSwAct/Val, filter=data-filter-type=ALWAYS, init-value=0}, required-interface=DoorAjarSwAct
      RRDoorAjarSwAct: nonqueued-receiver-com-spec{data-element=DoorAjarSwAct/Val, filter=data-filter-type=ALWAYS, init-value=0}, required-interface=DoorAjarSwAct
      SRSCnfmSwReq_67_2: nonqueued-receiver-com-spec{data-element=SRSCnfmSwReq_67_2/Val, filter=data-filter-type=ALWAYS, init-value=0}, required-interface=SRSCnfmSwReq_67_2
      SRSMode: nonqueued-receiver-com-spec{data-element=SRSCurMode/Val, filter=data-filter-type=ALWAYS, init-value=0}, required-interface=SRSCurMode
      SRSSlctSwReq: nonqueued-receiver-com-spec{data-element=SRSSlctSwReq/Val, filter=data-filter-type=ALWAYS, init-value=0}, required-interface=SRSSlctSwReq
      StPassCmprtMdCtrl_Md1_VCUConfig: parameter-require-com-spec{init-value=0, parameter=KeSMSbStPassCmprtMdVCUCfg/Val}, required-interface=KeSMSbStPassCmprtMdVCUCfg
      StPassCmprtMdCtrl_Md{10..13}_VCUConfig: parameter-require-com-spec{init-value=0, parameter=KeSMSbStPassCmprtMdVCUCfg/Val}, required-interface=KeSMSbStPassCmprtMdVCUCfg
      StPassCmprtMdCtrl_Md2_VCUConfig: parameter-require-com-spec{init-value=0, parameter=KeSMSbStPassCmprtMdVCUCfg/Val}, required-interface=KeSMSbStPassCmprtMdVCUCfg
      StPassCmprtMdCtrl_Md{27..29}_VCUConfig: parameter-require-com-spec{init-value=0, parameter=KeSMSbStPassCmprtMdVCUCfg/Val}, required-interface=KeSMSbStPassCmprtMdVCUCfg
      StPassCmprtMdCtrl_Md3_VCUConfig: parameter-require-com-spec{init-value=0, parameter=KeSMSbStPassCmprtMdVCUCfg/Val}, required-interface=KeSMSbStPassCmprtMdVCUCfg
      StPassCmprtMdCtrl_Md{30..32}_VCUConfig: parameter-require-com-spec{init-value=0, parameter=KeSMSbStPassCmprtMdVCUCfg/Val}, required-interface=KeSMSbStPassCmprtMdVCUCfg
      StPassCmprtMdCtrl_Md53_VCUConfig: parameter-require-com-spec{init-value=0, parameter=KeSMSbStPassCmprtMdVCUCfg/Val}, required-interface=KeSMSbStPassCmprtMdVCUCfg
      StPassCmprtMdCtrl_Md{56..58}_VCUConfig: parameter-require-com-spec{init-value=0, parameter=KeSMSbStPassCmprtMdVCUCfg/Val}, required-interface=KeSMSbStPassCmprtMdVCUCfg
      StPassCmprtMdCtrl_Md61_VCUConfig: parameter-require-com-spec{init-value=0, parameter=KeSMSbStPassCmprtMdVCUCfg/Val}, required-interface=KeSMSbStPassCmprtMdVCUCfg
      StPassCmprtMdCtrl_Md62_VCUConfig: parameter-require-com-spec{init-value=0, parameter=KeSMSbStPassCmprtMdVCUCfg/Val}, required-interface=KeSMSbStPassCmprtMdVCUCfg
      StPassCmprtMdCtrl_Md8_VCUConfig: parameter-require-com-spec{init-value=0, parameter=KeSMSbStPassCmprtMdVCUCfg/Val}, required-interface=KeSMSbStPassCmprtMdVCUCfg
      StPassCmprtMdCtrl_Md9_VCUConfig: parameter-require-com-spec{init-value=0, parameter=KeSMSbStPassCmprtMdVCUCfg/Val}, required-interface=KeSMSbStPassCmprtMdVCUCfg
      StPassCmprtMdHMIReq: nonqueued-receiver-com-spec{data-element=StPassCmprtMdHMIReq/Val, filter=data-filter-type=ALWAYS, init-value=0}, required-interface=StPassCmprtMdHMIReq
      StPassCmprtMdHMIReqExt: nonqueued-receiver-com-spec{data-element=StPassCmprtMdHMIReqExt/Val, filter=data-filter-type=ALWAYS, init-value=0}, required-interface=StPassCmprtMdHMIReqExt
      StPassCmprtMdHMIReqExt2: nonqueued-receiver-com-spec{data-element=StPassCmprtMdHMIReqExt2/Val, filter=data-filter-type=ALWAYS, init-value=0}, required-interface=StPassCmprtMdHMIReqExt2
      StSlctSwReq: nonqueued-receiver-com-spec{data-element=LugMdSelectSwt/Val, filter=data-filter-type=ALWAYS, init-value=0}, required-interface=LugMdSelectSwt
      StSlctSwReqV: nonqueued-receiver-com-spec{data-element=Validity/Val, filter=data-filter-type=ALWAYS, init-value=0}, required-interface=Validity
      StSrv_StMd1_Config: parameter-require-com-spec{init-value=0, parameter=KeSMSbStSrvCfg/Val}, required-interface=KeSMSbStSrvCfg
      StSrv_StMd{10..13}_Config: parameter-require-com-spec{init-value=0, parameter=KeSMSbStSrvCfg/Val}, required-interface=KeSMSbStSrvCfg
      StSrv_StMd2_Config: parameter-require-com-spec{init-value=0, parameter=KeSMSbStSrvCfg/Val}, required-interface=KeSMSbStSrvCfg
      StSrv_StMd{27..29}_Config: parameter-require-com-spec{init-value=0, parameter=KeSMSbStSrvCfg/Val}, required-interface=KeSMSbStSrvCfg
      StSrv_StMd3_Config: parameter-require-com-spec{init-value=0, parameter=KeSMSbStSrvCfg/Val}, required-interface=KeSMSbStSrvCfg
      StSrv_StMd{30..32}_Config: parameter-require-com-spec{init-value=0, parameter=KeSMSbStSrvCfg/Val}, required-interface=KeSMSbStSrvCfg
      StSrv_StMd8_Config: parameter-require-com-spec{init-value=0, parameter=KeSMSbStSrvCfg/Val}, required-interface=KeSMSbStSrvCfg
      StSrv_StMd9_Config: parameter-require-com-spec{init-value=0, parameter=KeSMSbStSrvCfg/Val}, required-interface=KeSMSbStSrvCfg
      StSrvReq_Md1: nonqueued-receiver-com-spec{data-element=StSrvReq/Val, filter=data-filter-type=ALWAYS, init-value=0}, required-interface=StSrvReq
      StSrvReq_Md{10..19}: nonqueued-receiver-com-spec{data-element=StSrvReq/Val, filter=data-filter-type=ALWAYS, init-value=0}, required-interface=StSrvReq
      StSrvReq_Md2: nonqueued-receiver-com-spec{data-element=StSrvReq/Val, filter=data-filter-type=ALWAYS, init-value=0}, required-interface=StSrvReq
      StSrvReq_Md{20..29}: nonqueued-receiver-com-spec{data-element=StSrvReq/Val, filter=data-filter-type=ALWAYS, init-value=0}, required-interface=StSrvReq
      StSrvReq_Md3: nonqueued-receiver-com-spec{data-element=StSrvReq/Val, filter=data-filter-type=ALWAYS, init-value=0}, required-interface=StSrvReq
      StSrvReq_Md{30..32}: nonqueued-receiver-com-spec{data-element=StSrvReq/Val, filter=data-filter-type=ALWAYS, init-value=0}, required-interface=StSrvReq
      StSrvReq_Md{4..9}: nonqueued-receiver-com-spec{data-element=StSrvReq/Val, filter=data-filter-type=ALWAYS, init-value=0}, required-interface=StSrvReq
      SysPwrMd: nonqueued-receiver-com-spec{data-element=PowerMode/Val, filter=data-filter-type=ALWAYS, init-value=0}, required-interface=PowerMode
      SysPwrMdV: nonqueued-receiver-com-spec{data-element=Validity/Val, filter=data-filter-type=ALWAYS, init-value=0}, required-interface=Validity
      ThdRLtStExpdSwReq: nonqueued-receiver-com-spec{data-element=MovSwAct/Val, filter=data-filter-type=ALWAYS, init-value=0}, required-interface=MovSwAct
      ThdRLtStExpdSwReqV: nonqueued-receiver-com-spec{data-element=MovSwActV/Val, filter=data-filter-type=ALWAYS, init-value=0}, required-interface=MovSwActV
      ThdRRtStExpdSwReq: nonqueued-receiver-com-spec{data-element=MovSwAct/Val, filter=data-filter-type=ALWAYS, init-value=0}, required-interface=MovSwAct
      ThdRRtStExpdSwReqV: nonqueued-receiver-com-spec{data-element=MovSwActV/Val, filter=data-filter-type=ALWAYS, init-value=0}, required-interface=MovSwActV
      unfold3LAvl: nonqueued-receiver-com-spec{data-element=ModeAdjustAvailable/Val, filter=data-filter-type=ALWAYS, init-value=0}, required-interface=ModeAdjustAvailable
      unfold3RAvl: nonqueued-receiver-com-spec{data-element=ModeAdjustAvailable/Val, filter=data-filter-type=ALWAYS, init-value=0}, required-interface=ModeAdjustAvailable
      VehMovState: nonqueued-receiver-com-spec{data-element=VehMovState/Val, filter=data-filter-type=ALWAYS, init-value=0}, required-interface=VehMovState
      Vip2LSwt: nonqueued-receiver-com-spec{data-element=Switch1/Val, filter=data-filter-type=ALWAYS, init-value=0}, required-interface=Switch1
      VipLtOutMdAvl: nonqueued-receiver-com-spec{data-element=ModeAdjustAvailable/Val, filter=data-filter-type=ALWAYS, init-value=0}, required-interface=ModeAdjustAvailable
      VipMdLtAvl: nonqueued-receiver-com-spec{data-element=Validity/Val, filter=data-filter-type=ALWAYS, init-value=0}, required-interface=Validity
      VipMdRtAvl: nonqueued-receiver-com-spec{data-element=Validity/Val, filter=data-filter-type=ALWAYS, init-value=0}, required-interface=Validity
      VipMdSwRtRclReq: nonqueued-receiver-com-spec{data-element=IfVeSMSbVipMdSwRtRclReq/Val, filter=data-filter-type=ALWAYS, init-value=0}, required-interface=IfVeSMSbVipMdSwRtRclReq
      VipRcvySwValid: nonqueued-receiver-com-spec{data-element=SwValid/Val, filter=data-filter-type=ALWAYS, init-value=0}, required-interface=SwValid
      VipRtOutMdAvl: nonqueued-receiver-com-spec{data-element=ModeAdjustAvailable/Val, filter=data-filter-type=ALWAYS, init-value=0}, required-interface=ModeAdjustAvailable
    behavior ModeInputHandle_InternalBehavior
      timing event TMT_ModelInputHandleRunnable: start-on-event=ModelInputHandleRunnable, period=0.01
      runnable ModelInputHandleRunnable: minimum-start-interval=0.01
        data-receive-point-by-arguments:
          180 x access:
            REC_AcsEntry2LSwt_Val: accessed-variable=AcsEntry2LSwt.Val
            REC_AcsEntry4s2LAvl_Val: accessed-variable=AcsEntry4s2LAvl.Val
            REC_AcsEntry4s2RAvl_Val: accessed-variable=AcsEntry4s2RAvl.Val
            REC_AcsEntryAll4sBwdAvl_Val: accessed-variable=AcsEntryAll4sBwdAvl.Val
            REC_AcsEntryAll4sFwdAvl_Val: accessed-variable=AcsEntryAll4sFwdAvl.Val
            REC_AcsEntrySwValid_Val: accessed-variable=AcsEntrySwValid.Val
            REC_AcsExit4s2LAvl_Val: accessed-variable=AcsExit4s2LAvl.Val
            REC_AcsExit4s2RAvl_Val: accessed-variable=AcsExit4s2RAvl.Val
            REC_AcsMdEntyAvl_Val: accessed-variable=AcsMdEntyAvl.Val
            REC_AcsMdEtrySwRtRclReq_Val: accessed-variable=AcsMdEtrySwRtRclReq.Val
            REC_AcsMdEtrySwRtRclReqV_Val: accessed-variable=AcsMdEtrySwRtRclReqV.Val
            REC_AcsMdExt4SSwRtRclReq_Val: accessed-variable=AcsMdExt4SSwRtRclReq.Val
            REC_AcsMdExt4SSwRtRclReqV_Val: accessed-variable=AcsMdExt4SSwRtRclReqV.Val
            REC_AcsMdExtAvl_Val: accessed-variable=AcsMdExtAvl.Val
            REC_AcsMdExtSwLtRclReq_Val: accessed-variable=AcsMdExtSwLtRclReq.Val
            REC_AcsMdExtSwLtRclReqV_Val: accessed-variable=AcsMdExtSwLtRclReqV.Val
            REC_AcsMdExtSwRtRclReq_Val: accessed-variable=AcsMdExtSwRtRclReq.Val
            REC_AcsMdExtSwRtRclReqV_Val: accessed-variable=AcsMdExtSwRtRclReqV.Val
            REC_Big4SeatAvl_Val: accessed-variable=Big4SeatAvl.Val
            REC_EZE4SSwReq_Val: accessed-variable=EZE4SSwReq.Val
            REC_FamilyMdLtAvl_Val: accessed-variable=FamilyMdLtAvl.Val
            REC_FamilyMdRtAvl_Val: accessed-variable=FamilyMdRtAvl.Val
            REC_HMIMode10RclReq_2R_Val: accessed-variable=HMIMode10RclReq_2R.Val
            REC_HMIMode10RclReq_Val: accessed-variable=HMIMode10RclReq_2L.Val
            REC_HMIMode11RclReq_2R_Val: accessed-variable=HMIMode11RclReq_2R.Val
            REC_HMIMode11RclReq_Val: accessed-variable=HMIMode11RclReq_2L.Val
            REC_HMIMode12RclReq_2R_Val: accessed-variable=HMIMode12RclReq_2R.Val
            REC_HMIMode12RclReq_Val: accessed-variable=HMIMode12RclReq_2L.Val
            REC_HMIMode13RclReq_2R_Val: accessed-variable=HMIMode13RclReq_2R.Val
            REC_HMIMode13RclReq_Val: accessed-variable=HMIMode13RclReq_2L.Val
            REC_HMIMode14RclReq_2R_Val: accessed-variable=HMIMode14RclReq_2R.Val
            REC_HMIMode14RclReq_Val: accessed-variable=HMIMode14RclReq_2L.Val
            REC_HMIMode15RclReq_2R_Val: accessed-variable=HMIMode15RclReq_2R.Val
            REC_HMIMode15RclReq_Val: accessed-variable=HMIMode15RclReq_2L.Val
            REC_HMIMode16RclReq_2R_Val: accessed-variable=HMIMode16RclReq_2R.Val
            REC_HMIMode16RclReq_Val: accessed-variable=HMIMode16RclReq_2L.Val
            REC_HMIMode17RclReq_2R_Val: accessed-variable=HMIMode17RclReq_2R.Val
            REC_HMIMode17RclReq_Val: accessed-variable=HMIMode17RclReq_2L.Val
            REC_HMIMode18RclReq_2R_Val: accessed-variable=HMIMode18RclReq_2R.Val
            REC_HMIMode18RclReq_Val: accessed-variable=HMIMode18RclReq_2L.Val
            REC_HMIMode19RclReq_2R_Val: accessed-variable=HMIMode19RclReq_2R.Val
            REC_HMIMode19RclReq_Val: accessed-variable=HMIMode19RclReq_2L.Val
            REC_HMIMode1RclReq_2R_Val: accessed-variable=HMIMode1RclReq_2R.Val
            REC_HMIMode1RclReq_Val: accessed-variable=HMIMode1RclReq_2L.Val
            REC_HMIMode20RclReq_2R_Val: accessed-variable=HMIMode20RclReq_2R.Val
            REC_HMIMode20RclReq_Val: accessed-variable=HMIMode20RclReq_2L.Val
            REC_HMIMode21RclReq_2R_Val: accessed-variable=HMIMode21RclReq_2R.Val
            REC_HMIMode21RclReq_Val: accessed-variable=HMIMode21RclReq_2L.Val
            REC_HMIMode22RclReq_2R_Val: accessed-variable=HMIMode22RclReq_2R.Val
            REC_HMIMode22RclReq_Val: accessed-variable=HMIMode22RclReq_2L.Val
            REC_HMIMode23RclReq_2R_Val: accessed-variable=HMIMode23RclReq_2R.Val
            REC_HMIMode23RclReq_Val: accessed-variable=HMIMode23RclReq_2L.Val
            REC_HMIMode24RclReq_2R_Val: accessed-variable=HMIMode24RclReq_2R.Val
            REC_HMIMode24RclReq_Val: accessed-variable=HMIMode24RclReq_2L.Val
            REC_HMIMode25RclReq_2R_Val: accessed-variable=HMIMode25RclReq_2R.Val
            REC_HMIMode25RclReq_Val: accessed-variable=HMIMode25RclReq_2L.Val
            REC_HMIMode26RclReq_2R_Val: accessed-variable=HMIMode26RclReq_2R.Val
            REC_HMIMode26RclReq_Val: accessed-variable=HMIMode26RclReq_2L.Val
            REC_HMIMode27RclReq_2R_Val: accessed-variable=HMIMode27RclReq_2R.Val
            REC_HMIMode27RclReq_Val: accessed-variable=HMIMode27RclReq_2L.Val
            REC_HMIMode28RclReq_2R_Val: accessed-variable=HMIMode28RclReq_2R.Val
            REC_HMIMode28RclReq_Val: accessed-variable=HMIMode28RclReq_2L.Val
            REC_HMIMode29RclReq_2R_Val: accessed-variable=HMIMode29RclReq_2R.Val
            REC_HMIMode29RclReq_Val: accessed-variable=HMIMode29RclReq_2L.Val
            REC_HMIMode2RclReq_2R_Val: accessed-variable=HMIMode2RclReq_2R.Val
            REC_HMIMode2RclReq_Val: accessed-variable=HMIMode2RclReq_2L.Val
            REC_HMIMode30RclReq_2R_Val: accessed-variable=HMIMode30RclReq_2R.Val
            REC_HMIMode30RclReq_Val: accessed-variable=HMIMode30RclReq_2L.Val
            REC_HMIMode31RclReq_2R_Val: accessed-variable=HMIMode31RclReq_2R.Val
            REC_HMIMode31RclReq_Val: accessed-variable=HMIMode31RclReq_2L.Val
            REC_HMIMode32RclReq_2R_Val: accessed-variable=HMIMode32RclReq_2R.Val
            REC_HMIMode32RclReq_Val: accessed-variable=HMIMode32RclReq_2L.Val
            REC_HMIMode3RclReq_2R_Val: accessed-variable=HMIMode3RclReq_2R.Val
            REC_HMIMode3RclReq_Val: accessed-variable=HMIMode3RclReq_2L.Val
            REC_HMIMode4RclReq_2R_Val: accessed-variable=HMIMode4RclReq_2R.Val
            REC_HMIMode4RclReq_Val: accessed-variable=HMIMode4RclReq_2L.Val
            REC_HMIMode5RclReq_2R_Val: accessed-variable=HMIMode5RclReq_2R.Val
            REC_HMIMode5RclReq_Val: accessed-variable=HMIMode5RclReq_2L.Val
            REC_HMIMode6RclReq_2R_Val: accessed-variable=HMIMode6RclReq_2R.Val
            REC_HMIMode6RclReq_Val: accessed-variable=HMIMode6RclReq_2L.Val
            REC_HMIMode7RclReq_2R_Val: accessed-variable=HMIMode7RclReq_2R.Val
            REC_HMIMode7RclReq_Val: accessed-variable=HMIMode7RclReq_2L.Val
            REC_HMIMode8RclReq_2R_Val: accessed-variable=HMIMode8RclReq_2R.Val
            REC_HMIMode8RclReq_Val: accessed-variable=HMIMode8RclReq_2L.Val
            REC_HMIMode9RclReq_2R_Val: accessed-variable=HMIMode9RclReq_2R.Val
            REC_HMIMode9RclReq_Val: accessed-variable=HMIMode9RclReq_2L.Val
            REC_IfVeSMSbRrRcvyMdSwRclReq_Val: accessed-variable=IfVeSMSbRrRcvyMdSwRclReq.Val
            REC_IfVeSMSbRrRcvyMdSwRclReqV_Val: accessed-variable=IfVeSMSbRrRcvyMdSwRclReqV.Val
            REC_IfVeSMSeStNumConfig_Val: accessed-variable=IfVeSMSeStNumConfig.Val
            REC_IfVeSMSeVipMdSwRtRclReqV_Val: accessed-variable=IfVeSMSeVipMdSwRtRclReqV.Val
            REC_IntimacyMdAvl_Val: accessed-variable=IntimacyLMdAvl.Val
            REC_IntimacyRMdAvl_Val: accessed-variable=IntimacyRMdAvl.Val
            REC_LckUlckActvtFunc_Val: accessed-variable=LckUlckActvtFunc.Val
            REC_LgrstCloseLtMdAvl_Val: accessed-variable=LgrstCloseLtMdAvl.Val
            REC_LgrstCloseRtMdAvl_Val: accessed-variable=LgrstCloseRtMdAvl.Val
            REC_LgrstOpenLtMdAvl_Val: accessed-variable=LgrstOpenLtMdAvl.Val
            REC_LgrstOpenRtMdAvl_Val: accessed-variable=LgrstOpenRtMdAvl.Val
            REC_LstLckChange_Val: accessed-variable=LstLckChange.Val
            REC_LstLckFunc_Val: accessed-variable=LstLckFunc.Val
            REC_LugMdLtAvl_Val: accessed-variable=LugMdLtAvl.Val
            REC_LugMdRtAvl_Val: accessed-variable=LugMdRtAvl.Val
            REC_LugMdSwRclReq_Val: accessed-variable=LugMdSwRclReq.Val
            REC_LugMdSwRclReqV_Val: accessed-variable=LugMdSwRclReqV.Val
            REC_LyingMdLtAvl_Val: accessed-variable=LyingMdLtAvl.Val
            REC_LyingMdRtAvl_Val: accessed-variable=LyingMdRtAvl.Val
            REC_M61WholeVehMemAvl_Val: accessed-variable=M61WholeVehMemAvl.Val
            REC_M62WholeVehMemAvl_Val: accessed-variable=M62WholeVehMemAvl.Val
            REC_ModeSrcTp_Val: accessed-variable=ModeSrcTp.Val
            REC_NotSecRowLeSeaOccStat_Val: accessed-variable=NotSecRowLeSeaOccStat.Val
            REC_NotSecRowRtSeaOccStat_Val: accessed-variable=NotSecRowRtSeaOccStat.Val
            REC_oModeState_Val: accessed-variable=oModeState.Val
            REC_PasReclinerAvl_Val: accessed-variable=PasReclinerAvl.Val
            REC_PasReclinerExitAvl_Val: accessed-variable=PasReclinerExitAvl.Val
            REC_PassStFldDnMovSwAct_Val: accessed-variable=PassStFldDnMovSwAct.Val
            REC_PassStFldDnMovSwActV_Val: accessed-variable=PassStFldDnMovSwActV.Val
            REC_PassStFldUpMovSwAct_Val: accessed-variable=PassStFldUpMovSwAct.Val
            REC_PassStFldUpMovSwActV_Val: accessed-variable=PassStFldUpMovSwActV.Val
            REC_RcvyMdLtAvl_Val: accessed-variable=RcvyMdLtAvl.Val
            REC_RcvyMdRtAvl_Val: accessed-variable=RcvyMdRtAvl.Val
            REC_RcvySwRtReq_Val: accessed-variable=RcvySwRtReq.Val
            REC_RcvySwRtReqV_Val: accessed-variable=RcvySwRtReqV.Val
            REC_Recovery2LSwt_Val: accessed-variable=Recovery2LSwt.Val
            REC_RLDoorAjarSwAct_Val: accessed-variable=RLDoorAjarSwAct.Val
            REC_RRDoorAjarSwAct_Val: accessed-variable=RRDoorAjarSwAct.Val
            REC_SRSCnfmSwReq_67_2_Val: accessed-variable=SRSCnfmSwReq_67_2.Val
            REC_SRSMode_Val: accessed-variable=SRSMode.Val
            REC_SRSSlctSwReq_Val: accessed-variable=SRSSlctSwReq.Val
            REC_StPassCmprtMdHMIReq_Val: accessed-variable=StPassCmprtMdHMIReq.Val
            REC_StPassCmprtMdHMIReqExt_Val: accessed-variable=StPassCmprtMdHMIReqExt.Val
            REC_StPassCmprtMdHMIReqExt2_Val: accessed-variable=StPassCmprtMdHMIReqExt2.Val
            REC_StSlctSwReq_Val: accessed-variable=StSlctSwReq.Val
            REC_StSlctSwReqV_Val: accessed-variable=StSlctSwReqV.Val
            REC_StSrvReq_Md1_Val: accessed-variable=StSrvReq_Md1.Val
            REC_StSrvReq_Md{10..19}_Val: accessed-variable=StSrvReq_Md{10..19}.Val
            REC_StSrvReq_Md2_Val: accessed-variable=StSrvReq_Md2.Val
            REC_StSrvReq_Md{20..29}_Val: accessed-variable=StSrvReq_Md{20..29}.Val
            REC_StSrvReq_Md3_Val: accessed-variable=StSrvReq_Md3.Val
            REC_StSrvReq_Md{30..32}_Val: accessed-variable=StSrvReq_Md{30..32}.Val
            REC_StSrvReq_Md{4..9}_Val: accessed-variable=StSrvReq_Md{4..9}.Val
            REC_SysPwrMd_Val: accessed-variable=SysPwrMd.Val
            REC_SysPwrMdV_Val: accessed-variable=SysPwrMdV.Val
            REC_ThdRLtStExpdSwReq_Val: accessed-variable=ThdRLtStExpdSwReq.Val
            REC_ThdRLtStExpdSwReqV_Val: accessed-variable=ThdRLtStExpdSwReqV.Val
            REC_ThdRRtStExpdSwReq_Val: accessed-variable=ThdRRtStExpdSwReq.Val
            REC_ThdRRtStExpdSwReqV_Val: accessed-variable=ThdRRtStExpdSwReqV.Val
            REC_unfold3LAvl_Val: accessed-variable=unfold3LAvl.Val
            REC_unfold3RAvl_Val: accessed-variable=unfold3RAvl.Val
            REC_VehMovState_Val: accessed-variable=VehMovState.Val
            REC_Vip2LSwt_Val: accessed-variable=Vip2LSwt.Val
            REC_VipLtOutMdAvl_Val: accessed-variable=VipLtOutMdAvl.Val
            REC_VipMdLtAvl_Val: accessed-variable=VipMdLtAvl.Val
            REC_VipMdRtAvl_Val: accessed-variable=VipMdRtAvl.Val
            REC_VipMdSwRtRclReq_Val: accessed-variable=VipMdSwRtRclReq.Val
            REC_VipRcvySwValid_Val: accessed-variable=VipRcvySwValid.Val
            REC_VipRtOutMdAvl_Val: accessed-variable=VipRtOutMdAvl.Val
        data-send-points:
          187 x access:
            SEND_acsEntry4s2LIntCnt_Val: accessed-variable=SwAcsEntry4s2LIntCnt.Val
            SEND_AcsEntry4s2LNotf1ChimeEventStat_Val: accessed-variable=AcsEntry4s2LNotf1ChimeEventStat.Val
            SEND_acsEntry4s2LReq_Val: accessed-variable=acsEntry4s2LReq.Val
            SEND_acsEntry4s2LSoftInt_Val: accessed-variable=acsEntry4s2LSoftInt.Val
            SEND_acsEntry4s2LSrcTp_Val: accessed-variable=acsEntry4s2LSrcTp.Val
            SEND_acsEntry4s2RIntCnt_Val: accessed-variable=SwAcsEntry4s2RIntCnt.Val
            SEND_AcsEntry4s2RNotf1ChimeEventStat_Val: accessed-variable=AcsEntry4s2RNotf1ChimeEventStat.Val
            SEND_acsEntry4s2RReq_Val: accessed-variable=acsEntry4s2RReq.Val
            SEND_acsEntry4s2RSoftInt_Val: accessed-variable=acsEntry4s2RSoftInt.Val
            SEND_acsEntry4s2RSrcTp_Val: accessed-variable=acsEntry4s2RSrcTp.Val
            SEND_AcsEntryAll4sBwdNotf1ChimeEventStat_Val: accessed-variable=AcsEntryAll4sBwdNotf1ChimeEventStat.Val
            SEND_acsEntryAll4sBwdReq_Val: accessed-variable=acsEntryAll4sBwdReq.Val
            SEND_acsEntryAll4sBwdReqSig_Val: accessed-variable=acsEntryAll4sBwdReqSig.Val
            SEND_acsEntryAll4sBwdSoftInt_Val: accessed-variable=acsEntryAll4sBwdSoftInt.Val
            SEND_AcsEntryAll4sFwdNotf1ChimeEventStat_Val: accessed-variable=AcsEntryAll4sFwdNotf1ChimeEventStat.Val
            SEND_acsEntryAll4sFwdReq_Val: accessed-variable=acsEntryAll4sFwdReq.Val
            SEND_acsEntryAll4sFwdReqSig_Val: accessed-variable=acsEntryAll4sFwdReqSig.Val
            SEND_acsEntryAll4sFwdSoftInt_Val: accessed-variable=acsEntryAll4sFwdSoftInt.Val
            SEND_acsEntyMdReq_Val: accessed-variable=acsEntyMdReq.Val
            SEND_acsEntyMdSrcTp_Val: accessed-variable=acsEntyMdSrcTp.Val
            SEND_acsEntySoftInt_Val: accessed-variable=acsEntySoftInt.Val
            SEND_acsExit4s2LIntCnt_Val: accessed-variable=SwAcsExit4s2LIntCnt.Val
            SEND_AcsExit4s2LNotf1ChimeEventStat_Val: accessed-variable=AcsExit4s2LNotf1ChimeEventStat.Val
            SEND_acsExit4s2LReq_Val: accessed-variable=acsExit4s2LReq.Val
            SEND_acsExit4s2LSoftInt_Val: accessed-variable=acsExit4s2LSoftInt.Val
            SEND_acsExit4s2LSrcTp_Val: accessed-variable=acsExit4s2LSrcTp.Val
            SEND_acsExit4s2RIntCnt_Val: accessed-variable=SwAcsExit4s2RIntCnt.Val
            SEND_AcsExit4s2RNotf1ChimeEventStat_Val: accessed-variable=AcsExit4s2RNotf1ChimeEventStat.Val
            SEND_acsExit4s2RReq_Val: accessed-variable=acsExit4s2RReq.Val
            SEND_acsExit4s2RSoftInt_Val: accessed-variable=acsExit4s2RSoftInt.Val
            SEND_acsExit4s2RSrcTp_Val: accessed-variable=acsExit4s2RSrcTp.Val
            SEND_acsExtMdReq_Val: accessed-variable=acsExtMdReq.Val
            SEND_acsExtMdSrcTp_Val: accessed-variable=acsExtMdSrcTp.Val
            SEND_acsExtSoftInt_Val: accessed-variable=acsExtSoftInt.Val
            SEND_acsMdEntryNotf1ChimeEventStat_Val: accessed-variable=acsMdEntryNotf1ChimeEventStat.Val
            SEND_acsMdExtNotf1ChimeEventStat_Val: accessed-variable=acsMdExtNotf1ChimeEventStat.Val
            SEND_AllLugMdReq_Val: accessed-variable=AllLugMdReq.Val
            SEND_AllLugSoftInt_Val: accessed-variable=AllLugSoftInt.Val
            SEND_AllLugSrcReqTp_Val: accessed-variable=AllLugSrcReqTp.Val
            SEND_AllVipMdReq_Val: accessed-variable=AllVipMdReq.Val
            SEND_AllVipSoftInt_Val: accessed-variable=AllVipSoftInt.Val
            SEND_AllVipSrcReqTp_Val: accessed-variable=AllVipSrcReqTp.Val
            SEND_Big4SeatNotf1ChimeEventStat_Val: accessed-variable=Big4SeatNotf1ChimeEventStat.Val
            SEND_Big4SeatReq_Val: accessed-variable=Big4SeatReq.Val
            SEND_Big4SeatSoftInt_Val: accessed-variable=Big4SeatSoftInt.Val
            SEND_Big4SeatsrcReqTp_Val: accessed-variable=Big4SeatsrcReqTp.Val
            SEND_ExVIPRNotf1ChimeEventStat_Val: accessed-variable=ExVIPRNotf1ChimeEventStat.Val
            SEND_ExVIPROutNotf1ChimeEventStat_Val: accessed-variable=ExVIPROutNotf1ChimeEventStat.Val
            SEND_ExVIPROutReq_Val: accessed-variable=ExVIPROutReq.Val
            SEND_ExVIPROutSoftInt_Val: accessed-variable=ExVIPROutSoftInt.Val
            SEND_ExVIPROutsrcReqTp_Val: accessed-variable=ExVIPROutsrcReqTp.Val
            SEND_ExVIPRReq_Val: accessed-variable=ExVIPRReq.Val
            SEND_ExVIPRSoftInt_Val: accessed-variable=ExVIPRSoftInt.Val
            SEND_ExVIPRsrcReqTp_Val: accessed-variable=ExVIPRsrcReqTp.Val
            SEND_FamilyMdNotf1ChimeEventStat_Val: accessed-variable=FamilyMdNotf1ChimeEventStat.Val
            SEND_IntimacyMdNotf1ChimeEventStat_Val: accessed-variable=IntimacyMdNotf1ChimeEventStat.Val
            SEND_IntimacyMdReq_Val: accessed-variable=IntimacyLtMdReq.Val
            SEND_IntimacyMdSrcTp_Val: accessed-variable=IntimacyLtMdSrcTp.Val
            SEND_IntimacyRtMdReq_Val: accessed-variable=IntimacyRtMdReq.Val
            SEND_IntimacyRtMdSrcTp_Val: accessed-variable=IntimacyRtMdSrcTp.Val
            SEND_IntimacyRtSoftInt_Val: accessed-variable=IntimacyRtSoftInt.Val
            SEND_IntimacySoftInt_Val: accessed-variable=IntimacyLtSoftInt.Val
            SEND_LfFamilyMdReq_Val: accessed-variable=LtFamilyMdReq.Val
            SEND_LfFamilySoftInt_Val: accessed-variable=LtFamilySoftInt.Val
            SEND_LfFamilySrcReqTp_Val: accessed-variable=LtFamilySrcReqTp.Val
            SEND_LfLyingMdReq_Val: accessed-variable=LtLyingMdReq.Val
            SEND_LfLyingSoftInt_Val: accessed-variable=LtLyingSoftInt.Val
            SEND_LfLyingSrcReqTp_Val: accessed-variable=LtLyingSrcReqTp.Val
            SEND_LgrstCloseLtMdReq_Val: accessed-variable=LgrstCloseLtMdReq.Val
            SEND_LgrstCloseLtMdSrcTp_Val: accessed-variable=LgrstCloseLtSrcReqTp.Val
            SEND_LgrstCloseLtSoftInt_Val: accessed-variable=LgrstCloseLtSoftInt.Val
            SEND_LgrstCloseRtMdReq_Val: accessed-variable=LgrstCloseRtMdReq.Val
            SEND_LgrstCloseRtMdSrcTp_Val: accessed-variable=LgrstCloseRtSrcReqTp.Val
            SEND_LgrstCloseRtSoftInt_Val: accessed-variable=LgrstCloseRtSoftInt.Val
            SEND_LgrstLtMdNotf1ChimeEventStat_Val: accessed-variable=LgrstLtMdNotf1ChimeEventStat.Val
            SEND_LgrstOpenLtMdReq_Val: accessed-variable=LgrstOpenLtMdReq.Val
            SEND_LgrstOpenLtMdSrcTp_Val: accessed-variable=LgrstOpenLtSrcReqTp.Val
            SEND_LgrstOpenLtSoftInt_Val: accessed-variable=LgrstOpenLtSoftInt.Val
            SEND_LgrstOpenRtMdReq_Val: accessed-variable=LgrstOpenRtMdReq.Val
            SEND_LgrstOpenRtMdSrcTp_Val: accessed-variable=LgrstOpenRtSrcReqTp.Val
            SEND_LgrstOpenRtSoftInt_Val: accessed-variable=LgrstOpenRtSoftInt.Val
            SEND_LgrstRtMdNotf1ChimeEventStat_Val: accessed-variable=LgrstRtMdNotf1ChimeEventStat.Val
            SEND_LtLugMdReq_Val: accessed-variable=LtLugMdReq.Val
            SEND_LtLugSoftInt_Val: accessed-variable=LtLugSoftInt.Val
            SEND_LtLugSrcReqTp_Val: accessed-variable=LtLugSrcReqTp.Val
            SEND_LtRcvyMdReq_Val: accessed-variable=LtRcvyMdReq.Val
            SEND_LtRcvySoftInt_Val: accessed-variable=LtRcvySoftInt.Val
            SEND_LtRcvySrcReqTp_Val: accessed-variable=LtRcvySrcReqTp.Val
            SEND_LtVipMdReq_Val: accessed-variable=LtVipMdReq.Val
            SEND_LtVipSoftInt_Val: accessed-variable=LtVipSoftInt.Val
            SEND_LtVipSrcReqTp_Val: accessed-variable=LtVipSrcReqTp.Val
            SEND_LugMdNotf1ChimeEventStat_Val: accessed-variable=LugMdNotf1ChimeEventStat.Val
            SEND_LyingMdNotf1ChimeEventStat_Val: accessed-variable=LyingMdNotf1ChimeEventStat.Val
            SEND_MdSWIntSrc_Val: accessed-variable=MdSWIntSrc.Val
            SEND_PasReclinerEntryNotf1ChimeEventStat_Val: accessed-variable=PasReclinerEntryNotf1ChimeEventStat.Val
            SEND_PasReclinerEntryReq_Val: accessed-variable=PasReclinerEntryReq.Val
            SEND_PasReclinerEntrySoftInt_Val: accessed-variable=PasReclinerEntrySoftInt.Val
            SEND_PasReclinerEntrySrcReqTp_Val: accessed-variable=PasReclinerEntrySrcReqTp.Val
            SEND_PasReclinerExitNotf1ChimeEventStat_Val: accessed-variable=PasReclinerExitNotf1ChimeEventStat.Val
            SEND_PasReclinerExitReq_Val: accessed-variable=PasReclinerExitReq.Val
            SEND_PasReclinerExitSoftInt_Val: accessed-variable=PasReclinerExitSoftInt.Val
            SEND_PasReclinerExitSrcReqTp_Val: accessed-variable=PasReclinerExitSrcReqTp.Val
            SEND_RcvyMdNotf1ChimeEventStat_Val: accessed-variable=RcvyMdNotf1ChimeEventStat.Val
            SEND_RtFamilyMdReq_Val: accessed-variable=RtFamilyMdReq.Val
            SEND_RtFamilySoftInt_Val: accessed-variable=RtFamilySoftInt.Val
            SEND_RtFamilySrcReqTp_Val: accessed-variable=RtFamilySrcReqTp.Val
            SEND_RtLugMdReq_Val: accessed-variable=RtLugMdReq.Val
            SEND_RtLugSoftInt_Val: accessed-variable=RtLugSoftInt.Val
            SEND_RtLugSrcReqTp_Val: accessed-variable=RtLugSrcReqTp.Val
            SEND_RtLyingMdReq_Val: accessed-variable=RtLyingMdReq.Val
            SEND_RtLyingSoftInt_Val: accessed-variable=RtLyingSoftInt.Val
            SEND_RtLyingSrcReqTp_Val: accessed-variable=RtLyingSrcReqTp.Val
            SEND_RtRcvyMdReq_Val: accessed-variable=RtRcvyMdReq.Val
            SEND_RtRcvySoftInt_Val: accessed-variable=RtRcvySoftInt.Val
            SEND_RtRcvySrcReqTp_Val: accessed-variable=RtRcvySrcReqTp.Val
            SEND_RtVipMdReq_Val: accessed-variable=RtVipMdReq.Val
            SEND_RtVipSoftInt_Val: accessed-variable=RtVipSoftInt.Val
            SEND_RtVipSrcReqTp_Val: accessed-variable=RtVipSrcReqTp.Val
            SEND_SRSAcsEntry4s2LIntCnt_Val: accessed-variable=SRSAcsEntry4s2LIntCnt.Val
            SEND_SRSAcsEntry4s2RIntCnt_Val: accessed-variable=SRSAcsEntry4s2RIntCnt.Val
            SEND_SRSAcsEntyIntCnt_Val: accessed-variable=SRSAcsEntyIntCnt.Val
            SEND_SRSAcsExit4s2LIntCnt_Val: accessed-variable=SRSAcsExit4s2LIntCnt.Val
            SEND_SRSAcsExit4s2RIntCnt_Val: accessed-variable=SRSAcsExit4s2RIntCnt.Val
            SEND_SRSAcsExtIntCnt_Val: accessed-variable=SRSAcsExtIntCnt.Val
            SEND_SRSAllLugIntCnt_Val: accessed-variable=SRSAllLugIntCnt.Val
            SEND_SRSAllVipIntCnt_Val: accessed-variable=SRSAllVipIntCnt.Val
            SEND_SRSIntimacyIntCnt_Val: accessed-variable=SRSIntimacyLtIntCnt.Val
            SEND_SRSIntimacyRtIntCnt_Val: accessed-variable=SRSIntimacyRtIntCnt.Val
            SEND_SRSLfFamilyIntCnt_Val: accessed-variable=SRSLtFamilyIntCnt.Val
            SEND_SRSLfLugIntCnt_Val: accessed-variable=SRSLtLugIntCnt.Val
            SEND_SRSLfLyingIntCnt_Val: accessed-variable=SRSLtLyingIntCnt.Val
            SEND_SRSLfRcvyIntCnt_Val: accessed-variable=SRSLtRcvyIntCnt.Val
            SEND_SRSLfVipIntCnt_Val: accessed-variable=SRSLtVipIntCnt.Val
            SEND_SRSLgrstCloseLtIntCnt_Val: accessed-variable=SRSLgrstCloseLtIntCnt.Val
            SEND_SRSLgrstCloseRtIntCnt_Val: accessed-variable=SRSLgrstCloseRtIntCnt.Val
            SEND_SRSLgrstOpenLtIntCnt_Val: accessed-variable=SRSLgrstOpenLtIntCnt.Val
            SEND_SRSLgrstOpenRtIntCnt_Val: accessed-variable=SRSLgrstOpenRtIntCnt.Val
            SEND_SRSRtFamilyIntCnt_Val: accessed-variable=SRSRtFamilyIntCnt.Val
            SEND_SRSRtLugIntCnt_Val: accessed-variable=SRSRtLugIntCnt.Val
            SEND_SRSRtLyingIntCnt_Val: accessed-variable=SRSRtLyingIntCnt.Val
            SEND_SRSRtRcvyIntCnt_Val: accessed-variable=SRSRtRcvyIntCnt.Val
            SEND_SRSRtVipIntCnt_Val: accessed-variable=SRSRtVipIntCnt.Val
            SEND_SwAcsEntyBIntCnt_Val: accessed-variable=SwAcsEntyBIntCnt.Val
            SEND_SwAcsEntyIntCnt_Val: accessed-variable=SwAcsEntyLIntCnt.Val
            SEND_SwAcsEntyRIntCnt_Val: accessed-variable=SwAcsEntyRIntCnt.Val
            SEND_SwAcsExtIntCnt_Val: accessed-variable=SwAcsExtLIntCnt.Val
            SEND_SwAcsExtRIntCnt_Val: accessed-variable=SwAcsExtRIntCnt.Val
            SEND_SwAllLugIntCnt_Val: accessed-variable=SwAllLugIntCnt.Val
            SEND_SwLfVipIntCnt_Val: accessed-variable=SwLfVipIntCnt.Val
            SEND_SwLtLugIntCnt_Val: accessed-variable=SwLtLugIntCnt.Val
            SEND_SwLtRcvyIntCnt_Val: accessed-variable=SwLtRcvyIntCnt.Val
            SEND_SwPasReclinerEntryCnt_Val: accessed-variable=SwPasReclinerEntryIntCnt.Val
            SEND_SwPasReclinerExitCnt_Val: accessed-variable=SwPasReclinerExitIntCnt.Val
            SEND_SwRtLugIntCnt_Val: accessed-variable=SwRtLugIntCnt.Val
            SEND_SwRtRcvyIntCnt_Val: accessed-variable=SwRtRcvyIntCnt.Val
            SEND_SwRtVipIntCnt_Val: accessed-variable=SwRtVipIntCnt.Val
            SEND_SwUnfold3LCnt_Val: accessed-variable=SwUnfold3LIntCnt.Val
            SEND_SwUnfold3RCnt_Val: accessed-variable=SwUnfold3RIntCnt.Val
            SEND_Unfold3LNotf1ChimeEventStat_Val: accessed-variable=Unfold3LNotf1ChimeEventStat.Val
            SEND_Unfold3LReq_Val: accessed-variable=Unfold3LReq.Val
            SEND_Unfold3LSoftInt_Val: accessed-variable=Unfold3LSoftInt.Val
            SEND_Unfold3LsrcReqTp_Val: accessed-variable=Unfold3LsrcReqTp.Val
            SEND_Unfold3RNotf1ChimeEventStat_Val: accessed-variable=Unfold3RNotf1ChimeEventStat.Val
            SEND_Unfold3RReq_Val: accessed-variable=Unfold3RReq.Val
            SEND_Unfold3RSoftInt_Val: accessed-variable=Unfold3RSoftInt.Val
            SEND_Unfold3RsrcReqTp_Val: accessed-variable=Unfold3RsrcReqTp.Val
            SEND_VIPAllOutNotf1ChimeEventStat_Val: accessed-variable=VIPAllOutNotf1ChimeEventStat.Val
            SEND_VIPAllOutReq_Val: accessed-variable=VIPAllOutReq.Val
            SEND_VIPAllOutSoftInt_Val: accessed-variable=VIPAllOutSoftInt.Val
            SEND_VIPAllOutsrcReqTp_Val: accessed-variable=VIPAllOutsrcReqTp.Val
            SEND_VIPLtOutNotf1ChimeEventStat_Val: accessed-variable=VIPLtOutNotf1ChimeEventStat.Val
            SEND_VIPLtOutReq_Val: accessed-variable=VIPLtOutReq.Val
            SEND_VIPLtOutSoftInt_Val: accessed-variable=VIPLtOutSoftInt.Val
            SEND_VIPLtOutsrcReqTp_Val: accessed-variable=VIPLtOutsrcReqTp.Val
            SEND_VipMdNotf1ChimeEventStat_Val: accessed-variable=VipMdNotf1ChimeEventStat.Val
            SEND_VIPRtOutNotf1ChimeEventStat_Val: accessed-variable=VIPRtOutNotf1ChimeEventStat.Val
            SEND_VIPRtOutReq_Val: accessed-variable=VIPRtOutReq.Val
            SEND_VIPRtOutSoftInt_Val: accessed-variable=VIPRtOutSoftInt.Val
            SEND_VIPRtOutsrcReqTp_Val: accessed-variable=VIPRtOutsrcReqTp.Val
            SEND_WholeVehMem1Notf1ChimeEventStat_Val: accessed-variable=WholeVehMem1Notf1ChimeEventStat.Val
            SEND_WholeVehMem1Req_Val: accessed-variable=WholeVehMem1Req.Val
            SEND_WholeVehMem1SoftInt_Val: accessed-variable=WholeVehMem1SoftInt.Val
            SEND_WholeVehMem1srcReqTp_Val: accessed-variable=WholeVehMem1srcReqTp.Val
            SEND_WholeVehMem2Notf1ChimeEventStat_Val: accessed-variable=WholeVehMem2Notf1ChimeEventStat.Val
            SEND_WholeVehMem2Req_Val: accessed-variable=WholeVehMem2Req.Val
            SEND_WholeVehMem2SoftInt_Val: accessed-variable=WholeVehMem2SoftInt.Val
            SEND_WholeVehMem2srcReqTp_Val: accessed-variable=WholeVehMem2srcReqTp.Val
        41 x parameter access:
          PA_KeSMSuButtonLongPressedThrshldTm_Val: accessed-parameter=KeSMSuButtonLongPressedThrshldTm.Val
          PA_KeSMSuFoldType_Val: accessed-parameter=KeSMSuFoldType.Val
          PA_KeSMSwSeatSMSSeatMdTrigGapTimer_Val: accessed-parameter=KeSMSwSeatSMSSeatMdTrigGapTimer.Val
          PA_KeSMSwSeatTrigWaitTimer_Val: accessed-parameter=KeSMSwSeatTrigWaitTimer.Val
          PA_KeSMSwSRSActiveValidTm_Val: accessed-parameter=KeSMSwSRSActiveValidTm.Val
          PA_StPassCmprtMdCtrl_Md1_VCUConfig_Val: accessed-parameter=StPassCmprtMdCtrl_Md1_VCUConfig.Val
          PA_StPassCmprtMdCtrl_Md{10..13}_VCUConfig_Val: accessed-parameter=StPassCmprtMdCtrl_Md{10..13}_VCUConfig.Val
          PA_StPassCmprtMdCtrl_Md2_VCUConfig_Val: accessed-parameter=StPassCmprtMdCtrl_Md2_VCUConfig.Val
          PA_StPassCmprtMdCtrl_Md{27..29}_VCUConfig_Val: accessed-parameter=StPassCmprtMdCtrl_Md{27..29}_VCUConfig.Val
          PA_StPassCmprtMdCtrl_Md3_VCUConfig_Val: accessed-parameter=StPassCmprtMdCtrl_Md3_VCUConfig.Val
          PA_StPassCmprtMdCtrl_Md{30..32}_VCUConfig_Val: accessed-parameter=StPassCmprtMdCtrl_Md{30..32}_VCUConfig.Val
          PA_StPassCmprtMdCtrl_Md53_VCUConfig_Val: accessed-parameter=StPassCmprtMdCtrl_Md53_VCUConfig.Val
          PA_StPassCmprtMdCtrl_Md{56..58}_VCUConfig_Val: accessed-parameter=StPassCmprtMdCtrl_Md{56..58}_VCUConfig.Val
          PA_StPassCmprtMdCtrl_Md61_VCUConfig_Val: accessed-parameter=StPassCmprtMdCtrl_Md61_VCUConfig.Val
          PA_StPassCmprtMdCtrl_Md62_VCUConfig_Val: accessed-parameter=StPassCmprtMdCtrl_Md62_VCUConfig.Val
          PA_StPassCmprtMdCtrl_Md8_VCUConfig_Val: accessed-parameter=StPassCmprtMdCtrl_Md8_VCUConfig.Val
          PA_StPassCmprtMdCtrl_Md9_VCUConfig_Val: accessed-parameter=StPassCmprtMdCtrl_Md9_VCUConfig.Val
          PA_StSrv_StMd1_Config_Val: accessed-parameter=StSrv_StMd1_Config.Val
          PA_StSrv_StMd{10..13}_Config_Val: accessed-parameter=StSrv_StMd{10..13}_Config.Val
          PA_StSrv_StMd2_Config_Val: accessed-parameter=StSrv_StMd2_Config.Val
          PA_StSrv_StMd{27..29}_Config_Val: accessed-parameter=StSrv_StMd{27..29}_Config.Val
          PA_StSrv_StMd3_Config_Val: accessed-parameter=StSrv_StMd3_Config.Val
          PA_StSrv_StMd{30..32}_Config_Val: accessed-parameter=StSrv_StMd{30..32}_Config.Val
          PA_StSrv_StMd8_Config_Val: accessed-parameter=StSrv_StMd8_Config.Val
          PA_StSrv_StMd9_Config_Val: accessed-parameter=StSrv_StMd9_Config.Val
  swc implementation ModeInputHandle_Implementation: behavior=ModeInputHandle_InternalBehavior
    code-descriptors:
      code Default: artifact-descriptors=autosar-engineering-object={short-label=Default, category=SWSRC}
package /PATAC/MSM/ModeAdjust/CalPortInterface
  4 x parameter interface:
    KeSMSbStPassCmprtMdVCUCfg
      parameter data prototype Val: sw-calibration-access=READ-WRITE, type=Boolean
    KeSMSbStSrvCfg
      parameter data prototype Val: sw-calibration-access=READ-WRITE, type=Boolean
    KeSMSuButtonLongPressedThrshldTm
      parameter data prototype Val: sw-calibration-access=READ-WRITE, type=UInt8
    KeSMSwSRSActiveValidTm
      parameter data prototype Val: sw-calibration-access=READ-WRITE, type=UInt16
package /PATAC/MSM/ModeAdjust/DataType
  15 x impl type, all with category=VALUE, base-type=UInt8, sw-calibration-access=READ-ONLY, type-emitter=RTE:
    CmprtMdHMIReqExt2Tp1: compu {0=CmprtMdHMIReqExt2Tp_NoAction, 1..75=CmprtMdHMIReqExt2Tp_Mode46..CmprtMdHMIReqExt2Tp_Mode120}
    CmprtMdHMIReqExtTp1: compu {0=CmprtMdHMIReqExtTp_NoAction, 1..18=CmprtMdHMIReqExtTp_Mode15..CmprtMdHMIReqExtTp_Mode32}
    CmprtMdHMIReqTp1: compu {0=CmprtMdHMIReqTp_NoAction, 1..14=CmprtMdHMIReqTp_Mode1..CmprtMdHMIReqTp_Mode14, 15=CmprtMdHMIReqTp_Stop}
    EZESwReq1: compu {0=EZESwReq_inactive, 1=EZE_IN, 2=EZE_OUT}
    LckUlckActvtFunc1: compu {0=ActvFunc_NoAct, 1=ActvFunc_PwrDorLckSw, 2=ActvFunc_DrvKeyCyl, 3=ActvFunc_RCSwitch, 4=ActvFunc_Emergency, 5=ActvFunc_ActvRmtKeyfob, 6=ActvFunc_PasvRmtKeyfob, 7=ActvFunc_EnhancedService, 8=ActvFunc_DelyLocking, 9=ActvFunc_Relocking, 10=ActvFunc_LockOutPrevent, 11=ActvFunc_ExteriorLockSw, 12=ActvFunc_VKMdev, 13=ActvFunc_ADL, 14=ActvFunc_Lckstupwlck, 15=ActvFunc_PasKeyCyl}
    LstLckFunc1: compu {0=LstLckFuncTyp_NoAction, 1=LstLckFuncTyp_PcUndblLock, 2=LstLckFuncTyp_PcUnlock, 3=LstLckFuncTyp_Unlock, 4=LstLckFuncTyp_UnlockDrv, 5=LstLckFuncTyp_UnlockPas, 6=LstLckFuncTyp_UnlockLr, 7=LstLckFuncTyp_UnlockRr, 8=LstLckFuncTyp_UnlockCargoLftgt, 9=LstLckFuncTyp_UnlockDrvSd, 10=LstLckFuncTyp_UnlockPasSd, 11=LstLckFuncTyp_UnlockNonDrv, 12=LstLckFuncTyp_UnlockAll, 13=LstLckFuncTyp_Lock, 14=LstLckFuncTyp_LockAll, 15=LstLckFuncTyp_DblLock, 16=LstLckFuncTyp_UnDblLock}
    LugSelectSw1: compu {0=LugSelectSw_NoAction, 1=LugSelectSw_Left, 2=LugSelectSw_Right, 3=LugSelectSw_All}
    MdReqTp1: compu {0=MdReqTp_NoAction, 1=MdReqTp_Start, 2=MdReqTp_Stop, 3=MdReqTp_Cancel}
    MdTp1: compu {0=MdTp_None, 1=MdTp_EzeEntry, 2=MdTp_EzeExt, 3=MdTp_Vip, 4=MdTp_Lug, 5=MdTp_Recovery, 6=MdTp_Intimacy, 7=MdTp_Family, 8=MdTp_Lying, 9=MdTp_LgrstOpenLt, 10=MdTp_LgrstCloseLt, 11=MdTp_LgrstOpenRt, 12=MdTp_LgrstCloseRt}
    PowerMode1: compu {0=PowerMode_Off, 1=PowerMode_Acc, 2=PowerMode_Run, 3=PowerMode_Crank, 4=PowerMode_Invalid}
    SeatOccupiedSts1: compu {0=SeatOccupiedSts_Unknown, 1=SeatOccupiedSts_Empty, 2=SeatOccupiedSts_Occupied, 3=SeatOccupiedSts_DataNotAvailable}
    SrcReqTp1: compu {0=SrcReqTp_None, 1=SrcReqTp_Local, 2=SrcReqTp_HMI2L, 3=SrcReqTp_HMI2R, 4=SrcReqTp_HMI, 5=SrcReqTp_Remote, 6=SrcReqTp_SRS}
    SRSCurMode1: compu {0=SRSMode_None, 1=SRSMode_EZEEntry, 2=SRSMode_EzeExt, 3=SRSMode_LfVip, 4=SRSMode_RtVip, 5=SRSMode_AllVip, 6=SRSMode_LfLug, 7=SRSMode_RtLug, 8=SRSMode_AllLug, 9=SRSMode_IntimacyL, 10=SRSMode_FamilyR, 11=SRSMode_FamilyL, 12=SRSMode_RcvyL, 13=SRSMode_RcvyR, 14=SRSMode_LyingL, 15=SRSMode_LyingR, 16=SRSMode_LgrstOpenLt, 17=SRSMode_LgrstCloseLt, 18=SRSMode_LgrstOpenRt, 19=SRSMode_LgrstCloseRt, 20=SRSMode_IntimacyR, 21=SRSMode_EzeEntry4s2L, 22=SRSMode_EzeExt4s2L, 23=SRSMode_EzeEntry4s2R, 24=SRSMode_EzeExt4s2R, 25=SRSMode_EzeEntryAll4sBwd, 26=SRSMode_EzeEntryAll4sFwd}
    SRSMode1: compu {0=SRSSlctSwStat_None, 1=SRSSlctSwStat_EzeEntry, 2=SRSSlctSwStat_EzeExt, 3=SRSSlctSwStat_LfVip, 4=SRSSlctSwStat_RtVip, 5=SRSSlctSwStat_AllVip, 6=SRSSlctSwStat_LfLug, 7=SRSSlctSwStat_RtLug, 8=SRSSlctSwStat_AllLug, 9=SRSSlctSwStat_IntimacyL, 10=SRSSlctSwStat_FamilyR, 11=SRSSlctSwStat_FamilyL, 12=SRSSlctSwStat_RcvyL, 13=SRSSlctSwStat_RcvyR, 14=SRSSlctSwStat_LyingL, 15=SRSSlctSwStat_LyingR, 16=SRSSlctSwStat_LgrstOpenLt, 17=SRSSlctSwStat_LgrstCloseLt, 18=SRSSlctSwStat_LgrstOpenRt, 19=SRSSlctSwStat_LgrstCloseRt, 20=SRSSlctSwStat_IntimacyR, 21=SRSSlctSwStat_EzeEntry4s2L, 22=SRSSlctSwStat_EzeExt4s2L, 23=SRSSlctSwStat_EzeEntry4s2R, 24=SRSSlctSwStat_EzeExt4s2R, 25=SRSSlctSwStat_EzeEntryAll4sBwd, 26=SRSSlctSwStat_EzeEntryAll4sFwd}
    VehMovState1: compu {0=VehMvSts_Parked, 1=VehMvSts_Neutral, 2=VehMvSts_Forward, 3=VehMvSts_Reverse, 4=VehMvSts_Invalid}
package /PATAC/MSM/ModeAdjust/PortInterface
  44 x sender receiver interface:
    AnyModeAjust: invalidation-policy{data-element=AnyModeAjust/Val, handle-invalid=DONT-INVALIDATE}
      data Val: type=Boolean
    DoorAjarSwAct: invalidation-policy{data-element=DoorAjarSwAct/Val, handle-invalid=DONT-INVALIDATE}
      data Val: type=Boolean
    EZE4SSwReq: invalidation-policy{data-element=EZE4SSwReq/Val, handle-invalid=DONT-INVALIDATE}
      data Val: type=EZESwReq1
    HMIRclReq: invalidation-policy{data-element=HMIRclReq/Val, handle-invalid=DONT-INVALIDATE}
      data Val: type=MdReqTp1
    IfVeSMSbAcsMdEtrySwRtRclReq: invalidation-policy{data-element=IfVeSMSbAcsMdEtrySwRtRclReq/Val, handle-invalid=DONT-INVALIDATE}
      data Val: type=Boolean
    IfVeSMSbAcsMdExt4SSwRtRclReq: invalidation-policy{data-element=IfVeSMSbAcsMdExt4SSwRtRclReq/Val, handle-invalid=DONT-INVALIDATE}
      data Val: type=Boolean
    IfVeSMSbAcsMdExt4SSwRtRclReqV: invalidation-policy{data-element=IfVeSMSbAcsMdExt4SSwRtRclReqV/Val, handle-invalid=DONT-INVALIDATE}
      data Val: type=Boolean
    IfVeSMSbAcsMdExtSwLtRclReq: invalidation-policy{data-element=IfVeSMSbAcsMdExtSwLtRclReq/Val, handle-invalid=DONT-INVALIDATE}
      data Val: type=Boolean
    IfVeSMSbAcsMdExtSwRtRclReq: invalidation-policy{data-element=IfVeSMSbAcsMdExtSwRtRclReq/Val, handle-invalid=DONT-INVALIDATE}
      data Val: type=Boolean
    IfVeSMSbLugMdSwRclReq: invalidation-policy{data-element=IfVeSMSbLugMdSwRclReq/Val, handle-invalid=DONT-INVALIDATE}
      data Val: type=Boolean
    IfVeSMSbVipMdSwRtRclReq: invalidation-policy{data-element=IfVeSMSbVipMdSwRtRclReq/Val, handle-invalid=DONT-INVALIDATE}
      data Val: type=Boolean
    IfVeSMSeAcsMdEtrySwRtRclReqV: invalidation-policy{data-element=IfVeSMSeAcsMdEtrySwRtRclReqV/Val, handle-invalid=DONT-INVALIDATE}
      data Val: type=Boolean
    IfVeSMSeAcsMdExtSwLtRclReqV: invalidation-policy{data-element=IfVeSMSeAcsMdExtSwLtRclReqV/Val, handle-invalid=DONT-INVALIDATE}
      data Val: type=UInt8
    IfVeSMSeAcsMdExtSwRtRclReqV: invalidation-policy{data-element=IfVeSMSeAcsMdExtSwRtRclReqV/Val, handle-invalid=DONT-INVALIDATE}
      data Val: type=Boolean
    IfVeSMSeLugMdSwRclReqV: invalidation-policy{data-element=IfVeSMSeLugMdSwRclReqV/Val, handle-invalid=DONT-INVALIDATE}
      data Val: type=UInt8
    IfVeSMSeStNumConfig: invalidation-policy{data-element=IfVeSMSeStNumConfig/Val, handle-invalid=DONT-INVALIDATE}
      data Val: type=IfVeSMSeStNumConfig
    IfVeSMSeVipMdSwRtRclReqV: invalidation-policy{data-element=IfVeSMSeVipMdSwRtRclReqV/Val, handle-invalid=DONT-INVALIDATE}
      data Val: type=Boolean
    IntEnable: invalidation-policy{data-element=IntEnable/Val, handle-invalid=DONT-INVALIDATE}
      data Val: type=IntEnable
    LckUlckActvtFunc: invalidation-policy{data-element=LckUlckActvtFunc/Val, handle-invalid=DONT-INVALIDATE}
      data Val: type=LckUlckActvtFunc1
    LstLckChange: invalidation-policy{data-element=LstLckChange/Val, handle-invalid=DONT-INVALIDATE}
      data Val: type=UInt8
    LstLckFunc: invalidation-policy{data-element=LstLckFunc/Val, handle-invalid=DONT-INVALIDATE}
      data Val: type=LstLckFunc1
    LugMdSelectSwt: invalidation-policy{data-element=LugMdSelectSwt/Val, handle-invalid=DONT-INVALIDATE}
      data Val: type=LugSelectSw1
    MdSWIntSrc: invalidation-policy{data-element=MdSWIntSrc/Val, handle-invalid=DONT-INVALIDATE}
      data Val: type=UInt16
    ModeAdjustAvailable: invalidation-policy{data-element=ModeAdjustAvailable/Val, handle-invalid=DONT-INVALIDATE}
      data Val: type=Boolean
    ModeSrcTp: invalidation-policy{data-element=ModeSrcTp/Val, handle-invalid=DONT-INVALIDATE}
      data Val: type=SrcReqTp1
    ModeState: invalidation-policy{data-element=ModeState/Val, handle-invalid=DONT-INVALIDATE}
      data Val: type=MdTp1
    MovSwAct: invalidation-policy{data-element=MovSwAct/Val, handle-invalid=DONT-INVALIDATE}
      data Val: type=Boolean
    MovSwActV: invalidation-policy{data-element=MovSwActV/Val, handle-invalid=DONT-INVALIDATE}
      data Val: type=Boolean
    Notf1ChimeEventStat: invalidation-policy{data-element=Notf1ChimeEventStat/Val, handle-invalid=DONT-INVALIDATE}
      data Val: type=Boolean
    PowerMode: invalidation-policy{data-element=PowerMode/Val, handle-invalid=DONT-INVALIDATE}
      data Val: type=PowerMode1
    SeatOccupiedState: invalidation-policy{data-element=SeatOccupiedState/Val, handle-invalid=DONT-INVALIDATE}
      data Val: type=SeatOccupiedSts1
    SRSCnfmSwReq_67_2: invalidation-policy{data-element=SRSCnfmSwReq_67_2/Val, handle-invalid=DONT-INVALIDATE}
      data Val: type=Boolean
    SRSCurMode: invalidation-policy{data-element=SRSCurMode/Val, handle-invalid=DONT-INVALIDATE}
      data Val: type=SRSCurMode1
    SRSSlctSwReq: invalidation-policy{data-element=SRSSlctSwReq/Val, handle-invalid=DONT-INVALIDATE}
      data Val: type=SRSMode1
    StPassCmprtMdHMIReq: invalidation-policy{data-element=StPassCmprtMdHMIReq/Val, handle-invalid=DONT-INVALIDATE}
      data Val: type=CmprtMdHMIReqTp1
    StPassCmprtMdHMIReqExt: invalidation-policy{data-element=StPassCmprtMdHMIReqExt/Val, handle-invalid=DONT-INVALIDATE}
      data Val: type=CmprtMdHMIReqExtTp1
    StPassCmprtMdHMIReqExt2: invalidation-policy{data-element=StPassCmprtMdHMIReqExt2/Val, handle-invalid=DONT-INVALIDATE}
      data Val: type=CmprtMdHMIReqExt2Tp1
    StSrvReq: invalidation-policy{data-element=StSrvReq/Val, handle-invalid=DONT-INVALIDATE}
      data Val: type=Boolean
    Switch: invalidation-policy{data-element=Switch/Val, handle-invalid=DONT-INVALIDATE}
      data Val: type=Boolean
    Switch1: invalidation-policy{data-element=Switch1/Val, handle-invalid=DONT-INVALIDATE}
      data Val: type=UInt8
    SwModeIntCnt: invalidation-policy{data-element=SwModeIntCnt/Val, handle-invalid=DONT-INVALIDATE}
      data Val: type=IntCnt
    SwValid: invalidation-policy{data-element=SwValid/Val, handle-invalid=DONT-INVALIDATE}
      data Val: type=UInt8
    Validity: invalidation-policy{data-element=Validity/Val, handle-invalid=DONT-INVALIDATE}
      data Val: type=Boolean
    VehMovState: invalidation-policy{data-element=VehMovState/Val, handle-invalid=DONT-INVALIDATE}
      data Val: type=VehMovState1
package /PATAC/MSM/PortInterfaces
  parameter interface IfKeSMSwSeatSMSSeatMdTrigGapTimer
    parameter data prototype Val: sw-calibration-access=READ-WRITE, type=UInt16
  parameter interface IfKeSMSwSeatTrigWaitTimer
    parameter data prototype Val: sw-calibration-access=READ-WRITE, type=UInt16
  sender receiver interface SeatSwReq: invalidation-policy{data-element=SeatSwReq/Val, handle-invalid=DONT-INVALIDATE}
    data Val: type=UInt8
  sender receiver interface SeatSwReqV: invalidation-policy{data-element=SeatSwReqV/Val, handle-invalid=DONT-INVALIDATE}
    data Val: type=Boolean
